[part 2 of 2: packages /AUTOSAR/Csm/ServiceSwComponentTypes_Blueprint to /AUTOSAR/NvM/ServiceSwComponentTypes_Blueprint]
AUTOSAR XML (schema 00046)
package /AUTOSAR/Csm/ServiceSwComponentTypes_Blueprint
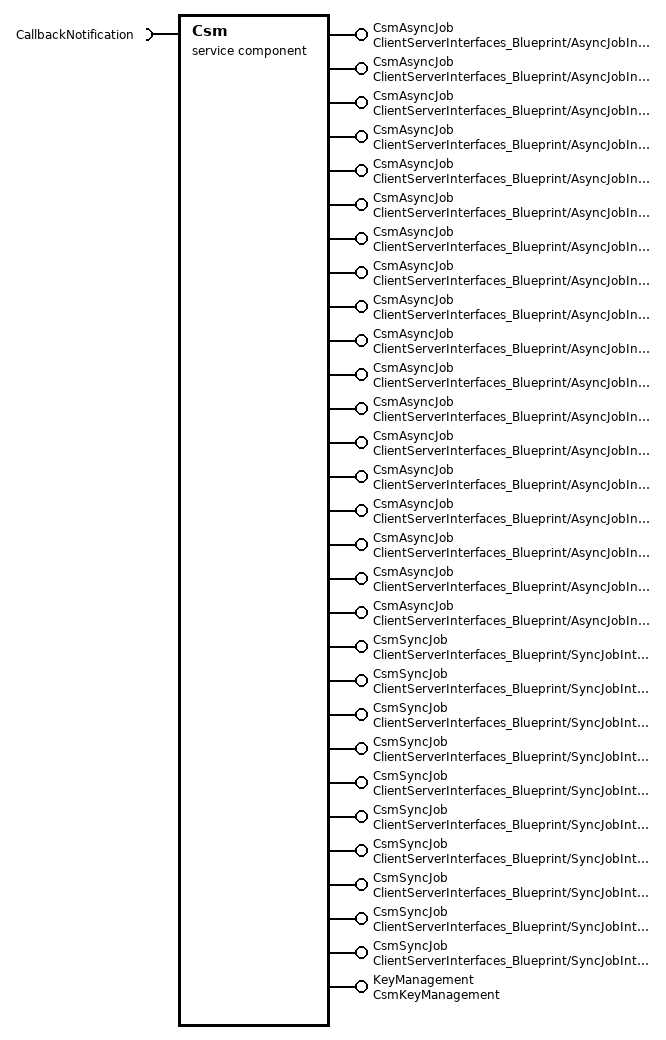
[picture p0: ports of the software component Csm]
  service sw component type Csm
    require port CallbackNotification: variation-point=blueprint-condition=p=l-1=({ecuc(Csm/CsmJobs/CsmJob.CsmProcessingMode)} == CRYPTO_PROCESSING_ASYNC), required-interface=CallbackNotification  # Port for the callback notification.
    29 x provide port:
      CsmAsyncJob: variation-point={short-label=AsyncJobInterface_AsyncCsmHash, blueprint-condition=p=l-1=({ecuc(Csm/CsmJobs/CsmJob.CsmJobInterfaceUsePort)} == CRYPTO_USE_PORT_OPTIMIZED) &&({ecuc(Csm/CsmJobs/CsmJob.CsmJobPrimitiveRef)} != NULL)}, provided-interface=ClientServerInterfaces_Blueprint/AsyncJobInterface  # Port related to a specific cryptographic job to execute the assigned cryptographic calculations asynchronously.
      CsmAsyncJob: variation-point={short-label=AsyncJobInterface_AsyncCsmMacGenerate, blueprint-condition=p=l-1=({ecuc(Csm/CsmJobs/CsmJob.CsmJobInterfaceUsePort)} == CRYPTO_USE_PORT_OPTIMIZED) &&({ecuc(Csm/CsmJobs/CsmJob.CsmJobPrimitiveRef)} != NULL)}, provided-interface=ClientServerInterfaces_Blueprint/AsyncJobInterface  # Port related to a specific cryptographic job to execute the assigned cryptographic calculations asynchronously.
      CsmAsyncJob: variation-point={short-label=AsyncJobInterface_AsyncCsmMacVerify, blueprint-condition=p=l-1=({ecuc(Csm/CsmJobs/CsmJob.CsmJobInterfaceUsePort)} == CRYPTO_USE_PORT_OPTIMIZED) &&({ecuc(Csm/CsmJobs/CsmJob.CsmJobPrimitiveRef)} != NULL)}, provided-interface=ClientServerInterfaces_Blueprint/AsyncJobInterface  # Port related to a specific cryptographic job to execute the assigned cryptographic calculations asynchronously.
      CsmAsyncJob: variation-point={short-label=AsyncJobInterface_AsyncCsmEncrypt, blueprint-condition=p=l-1=({ecuc(Csm/CsmJobs/CsmJob.CsmJobInterfaceUsePort)} == CRYPTO_USE_PORT_OPTIMIZED) &&({ecuc(Csm/CsmJobs/CsmJob.CsmJobPrimitiveRef)} != NULL)}, provided-interface=ClientServerInterfaces_Blueprint/AsyncJobInterface  # Port related to a specific cryptographic job to execute the assigned cryptographic calculations asynchronously.
      CsmAsyncJob: variation-point={short-label=AsyncJobInterface_AsyncCsmDecrypt, blueprint-condition=p=l-1=({ecuc(Csm/CsmJobs/CsmJob.CsmJobInterfaceUsePort)} == CRYPTO_USE_PORT_OPTIMIZED) &&({ecuc(Csm/CsmJobs/CsmJob.CsmJobPrimitiveRef)} != NULL)}, provided-interface=ClientServerInterfaces_Blueprint/AsyncJobInterface  # Port related to a specific cryptographic job to execute the assigned cryptographic calculations asynchronously.
      CsmAsyncJob: variation-point={short-label=AsyncJobInterface_AsyncCsmAEADEncrypt, blueprint-condition=p=l-1=({ecuc(Csm/CsmJobs/CsmJob.CsmJobInterfaceUsePort)} == CRYPTO_USE_PORT_OPTIMIZED) &&({ecuc(Csm/CsmJobs/CsmJob.CsmJobPrimitiveRef)} != NULL)}, provided-interface=ClientServerInterfaces_Blueprint/AsyncJobInterface  # Port related to a specific cryptographic job to execute the assigned cryptographic calculations asynchronously.
      CsmAsyncJob: variation-point={short-label=AsyncJobInterface_AsyncCsmAEADDecrypt, blueprint-condition=p=l-1=({ecuc(Csm/CsmJobs/CsmJob.CsmJobInterfaceUsePort)} == CRYPTO_USE_PORT_OPTIMIZED) &&({ecuc(Csm/CsmJobs/CsmJob.CsmJobPrimitiveRef)} != NULL)}, provided-interface=ClientServerInterfaces_Blueprint/AsyncJobInterface  # Port related to a specific cryptographic job to execute the assigned cryptographic calculations asynchronously.
      CsmAsyncJob: variation-point={short-label=AsyncJobInterface_AsyncCsmSignatureGenerate, blueprint-condition=p=l-1=({ecuc(Csm/CsmJobs/CsmJob.CsmJobInterfaceUsePort)} == CRYPTO_USE_PORT_OPTIMIZED) &&({ecuc(Csm/CsmJobs/CsmJob.CsmJobPrimitiveRef)} != NULL)}, provided-interface=ClientServerInterfaces_Blueprint/AsyncJobInterface  # Port related to a specific cryptographic job to execute the assigned cryptographic calculations asynchronously.
      CsmAsyncJob: variation-point={short-label=AsyncJobInterface_AsyncCsmSignatureVerify, blueprint-condition=p=l-1=({ecuc(Csm/CsmJobs/CsmJob.CsmJobInterfaceUsePort)} == CRYPTO_USE_PORT_OPTIMIZED) &&({ecuc(Csm/CsmJobs/CsmJob.CsmJobPrimitiveRef)} != NULL)}, provided-interface=ClientServerInterfaces_Blueprint/AsyncJobInterface  # Port related to a specific cryptographic job to execute the assigned cryptographic calculations asynchronously.
      CsmAsyncJob: variation-point={short-label=AsyncJobInterface_AsyncCsmRandomGenerate, blueprint-condition=p=l-1=({ecuc(Csm/CsmJobs/CsmJob.CsmJobInterfaceUsePort)} == CRYPTO_USE_PORT_OPTIMIZED) &&({ecuc(Csm/CsmJobs/CsmJob.CsmJobPrimitiveRef)} != NULL)}, provided-interface=ClientServerInterfaces_Blueprint/AsyncJobInterface  # Port related to a specific cryptographic job to execute the assigned cryptographic calculations asynchronously.
      CsmAsyncJob: variation-point={short-label=AsyncJobInterface_JobCertificateParse, blueprint-condition=p=l-1=({ecuc(Csm/CsmJobs/CsmJob.CsmJobInterfaceUsePort)} == CRYPTO_USE_PORT_OPTIMIZED) &&({ecuc(Csm/CsmJobs/CsmJob.CsmJobPrimitiveRef)} != NULL)}, provided-interface=ClientServerInterfaces_Blueprint/AsyncJobInterface  # Port related to a specific cryptographic job to execute the assigned cryptographic calculations asynchronously.
      CsmAsyncJob: variation-point={short-label=AsyncJobInterface_JobCertificateVerify, blueprint-condition=p=l-1=({ecuc(Csm/CsmJobs/CsmJob.CsmJobInterfaceUsePort)} == CRYPTO_USE_PORT_OPTIMIZED) &&({ecuc(Csm/CsmJobs/CsmJob.CsmJobPrimitiveRef)} != NULL)}, provided-interface=ClientServerInterfaces_Blueprint/AsyncJobInterface  # Port related to a specific cryptographic job to execute the assigned cryptographic calculations asynchronously.
      CsmAsyncJob: variation-point={short-label=AsyncJobInterface_JobKeyDerive, blueprint-condition=p=l-1=({ecuc(Csm/CsmJobs/CsmJob.CsmJobInterfaceUsePort)} == CRYPTO_USE_PORT_OPTIMIZED) &&({ecuc(Csm/CsmJobs/CsmJob.CsmJobPrimitiveRef)} != NULL)}, provided-interface=ClientServerInterfaces_Blueprint/AsyncJobInterface  # Port related to a specific cryptographic job to execute the assigned cryptographic calculations asynchronously.
      CsmAsyncJob: variation-point={short-label=AsyncJobInterface_JobKeyExchangeCalcPubVal, blueprint-condition=p=l-1=({ecuc(Csm/CsmJobs/CsmJob.CsmJobInterfaceUsePort)} == CRYPTO_USE_PORT_OPTIMIZED) &&({ecuc(Csm/CsmJobs/CsmJob.CsmJobPrimitiveRef)} != NULL)}, provided-interface=ClientServerInterfaces_Blueprint/AsyncJobInterface  # Port related to a specific cryptographic job to execute the assigned cryptographic calculations asynchronously.
      CsmAsyncJob: variation-point={short-label=AsyncJobInterface_JobKeyExchangeCalcSecret, blueprint-condition=p=l-1=({ecuc(Csm/CsmJobs/CsmJob.CsmJobInterfaceUsePort)} == CRYPTO_USE_PORT_OPTIMIZED) &&({ecuc(Csm/CsmJobs/CsmJob.CsmJobPrimitiveRef)} != NULL)}, provided-interface=ClientServerInterfaces_Blueprint/AsyncJobInterface  # Port related to a specific cryptographic job to execute the assigned cryptographic calculations asynchronously.
      CsmAsyncJob: variation-point={short-label=AsyncJobInterface_JobKeyGenerate, blueprint-condition=p=l-1=({ecuc(Csm/CsmJobs/CsmJob.CsmJobInterfaceUsePort)} == CRYPTO_USE_PORT_OPTIMIZED) &&({ecuc(Csm/CsmJobs/CsmJob.CsmJobPrimitiveRef)} != NULL)}, provided-interface=ClientServerInterfaces_Blueprint/AsyncJobInterface  # Port related to a specific cryptographic job to execute the assigned cryptographic calculations asynchronously.
      CsmAsyncJob: variation-point={short-label=AsyncJobInterface_JobKeySetValid, blueprint-condition=p=l-1=({ecuc(Csm/CsmJobs/CsmJob.CsmJobInterfaceUsePort)} == CRYPTO_USE_PORT_OPTIMIZED) &&({ecuc(Csm/CsmJobs/CsmJob.CsmJobPrimitiveRef)} != NULL)}, provided-interface=ClientServerInterfaces_Blueprint/AsyncJobInterface  # Port related to a specific cryptographic job to execute the assigned cryptographic calculations asynchronously.
      CsmAsyncJob: variation-point={short-label=AsyncJobInterface_JobRandomSeed, blueprint-condition=p=l-1=({ecuc(Csm/CsmJobs/CsmJob.CsmJobInterfaceUsePort)} == CRYPTO_USE_PORT_OPTIMIZED) &&({ecuc(Csm/CsmJobs/CsmJob.CsmJobPrimitiveRef)} != NULL)}, provided-interface=ClientServerInterfaces_Blueprint/AsyncJobInterface  # Port related to a specific cryptographic job to execute the assigned cryptographic calculations asynchronously.
      CsmSyncJob: variation-point={short-label=SyncJobInterface_SyncCsmHash, blueprint-condition=p=l-1=({ecuc(Csm/CsmJobs/CsmJob.CsmJobInterfaceUsePort)} == CRYPTO_USE_PORT) &&({ecuc(Csm/CsmJobs/CsmJob.CsmJobPrimitiveRef)} != NULL)}, provided-interface=ClientServerInterfaces_Blueprint/SyncJobInterface  # Port related to a specific cryptographic job to execute the assigned cryptographic calculations synchronously.
      CsmSyncJob: variation-point={short-label=SyncJobInterface_SyncCsmMacGenerate, blueprint-condition=p=l-1=({ecuc(Csm/CsmJobs/CsmJob.CsmJobInterfaceUsePort)} == CRYPTO_USE_PORT) &&({ecuc(Csm/CsmJobs/CsmJob.CsmJobPrimitiveRef)} != NULL)}, provided-interface=ClientServerInterfaces_Blueprint/SyncJobInterface  # Port related to a specific cryptographic job to execute the assigned cryptographic calculations synchronously.
      CsmSyncJob: variation-point={short-label=SyncJobInterface_SyncCsmMacVerify, blueprint-condition=p=l-1=({ecuc(Csm/CsmJobs/CsmJob.CsmJobInterfaceUsePort)} == CRYPTO_USE_PORT) &&({ecuc(Csm/CsmJobs/CsmJob.CsmJobPrimitiveRef)} != NULL)}, provided-interface=ClientServerInterfaces_Blueprint/SyncJobInterface  # Port related to a specific cryptographic job to execute the assigned cryptographic calculations synchronously.
      CsmSyncJob: variation-point={short-label=SyncJobInterface_SyncCsmEncrypt, blueprint-condition=p=l-1=({ecuc(Csm/CsmJobs/CsmJob.CsmJobInterfaceUsePort)} == CRYPTO_USE_PORT) &&({ecuc(Csm/CsmJobs/CsmJob.CsmJobPrimitiveRef)} != NULL)}, provided-interface=ClientServerInterfaces_Blueprint/SyncJobInterface  # Port related to a specific cryptographic job to execute the assigned cryptographic calculations synchronously.
      CsmSyncJob: variation-point={short-label=SyncJobInterface_SyncCsmDecrypt, blueprint-condition=p=l-1=({ecuc(Csm/CsmJobs/CsmJob.CsmJobInterfaceUsePort)} == CRYPTO_USE_PORT) &&({ecuc(Csm/CsmJobs/CsmJob.CsmJobPrimitiveRef)} != NULL)}, provided-interface=ClientServerInterfaces_Blueprint/SyncJobInterface  # Port related to a specific cryptographic job to execute the assigned cryptographic calculations synchronously.
      CsmSyncJob: variation-point={short-label=SyncJobInterface_SyncCsmAEADEncrypt, blueprint-condition=p=l-1=({ecuc(Csm/CsmJobs/CsmJob.CsmJobInterfaceUsePort)} == CRYPTO_USE_PORT) &&({ecuc(Csm/CsmJobs/CsmJob.CsmJobPrimitiveRef)} != NULL)}, provided-interface=ClientServerInterfaces_Blueprint/SyncJobInterface  # Port related to a specific cryptographic job to execute the assigned cryptographic calculations synchronously.
      CsmSyncJob: variation-point={short-label=SyncJobInterface_SyncCsmAEADDecrypt, blueprint-condition=p=l-1=({ecuc(Csm/CsmJobs/CsmJob.CsmJobInterfaceUsePort)} == CRYPTO_USE_PORT) &&({ecuc(Csm/CsmJobs/CsmJob.CsmJobPrimitiveRef)} != NULL)}, provided-interface=ClientServerInterfaces_Blueprint/SyncJobInterface  # Port related to a specific cryptographic job to execute the assigned cryptographic calculations synchronously.
      CsmSyncJob: variation-point={short-label=SyncJobInterface_SyncCsmSignatureGenerate, blueprint-condition=p=l-1=({ecuc(Csm/CsmJobs/CsmJob.CsmJobInterfaceUsePort)} == CRYPTO_USE_PORT) &&({ecuc(Csm/CsmJobs/CsmJob.CsmJobPrimitiveRef)} != NULL)}, provided-interface=ClientServerInterfaces_Blueprint/SyncJobInterface  # Port related to a specific cryptographic job to execute the assigned cryptographic calculations synchronously.
      CsmSyncJob: variation-point={short-label=SyncJobInterface_SyncCsmSignatureVerify, blueprint-condition=p=l-1=({ecuc(Csm/CsmJobs/CsmJob.CsmJobInterfaceUsePort)} == CRYPTO_USE_PORT) &&({ecuc(Csm/CsmJobs/CsmJob.CsmJobPrimitiveRef)} != NULL)}, provided-interface=ClientServerInterfaces_Blueprint/SyncJobInterface  # Port related to a specific cryptographic job to execute the assigned cryptographic calculations synchronously.
      CsmSyncJob: variation-point={short-label=SyncJobInterface_SyncCsmRandomGenerate, blueprint-condition=p=l-1=({ecuc(Csm/CsmJobs/CsmJob.CsmJobInterfaceUsePort)} == CRYPTO_USE_PORT) &&({ecuc(Csm/CsmJobs/CsmJob.CsmJobPrimitiveRef)} != NULL)}, provided-interface=ClientServerInterfaces_Blueprint/SyncJobInterface  # Port related to a specific cryptographic job to execute the assigned cryptographic calculations synchronously.
      KeyManagement: variation-point=blueprint-condition=p=l-1={ecuc(Csm/CsmKeys/CsmKey.CsmKeyUsePort)} == TRUE, provided-interface=CsmKeyManagement  # Port related to a specific cryptographic key to execute the key management functions synchronously.
    behavior CsmInternalBehavior
      port-api-options:
        {port-arg-values=[{value=undefined, value-type=uint32}, {value=undefined, value-type=Crypto_OperationModeType}], port=Csm/CsmAsyncJob}
        {port-arg-values=[{value=undefined, value-type=uint32}, {value=undefined, value-type=Crypto_OperationModeType}], port=Csm/CsmSyncJob}
        {port-defined-argument-value{value=undefined, value-type=uint32}, port=KeyManagement}
package /AUTOSAR/Mirror/ClientServerInterfaces_Blueprint
  client server interface MirrorControl: is-service=true  # Provides access to the control functions of the Bus Mirroring module.
    18 x operation:
      AddCanMaskFilter: possible-error=[MirrorControl/E_OK, MirrorControl/E_NOT_OK]  # Creates a CAN ID mask filter.
        4 x arg:
          network: type=NetworkHandleType, direction=IN  # ComM channel that corresponds to the CAN bus to which the filter shall be attached.
          filterId: category=DATA_REFERENCE, type=Mirror_uint8Ptr, direction=OUT  # ID of the newly created filter.
          id: type=Mirror_CanIdType, direction=IN  # CAN ID used to match a received or transmitted CAN ID.
          mask: type=Mirror_CanIdType, direction=IN  # Mask that defines the bits of 'id' that are relevant for comparison with the actual CAN ID.
      AddCanRangeFilter: possible-error=[MirrorControl/E_OK, MirrorControl/E_NOT_OK]  # Creates a CAN ID range filter.
        4 x arg:
          network: type=NetworkHandleType, direction=IN  # ComM channel that corresponds to the CAN bus to which the filter shall be attached.
          filterId: category=DATA_REFERENCE, type=Mirror_uint8Ptr, direction=OUT  # ID of the newly created filter.
          lowerId: type=Mirror_CanIdType, direction=IN  # Lower CAN ID of the range.
          upperId: type=Mirror_CanIdType, direction=IN  # Upper CAN ID of the range.
      AddFlexRayFilter: possible-error=[MirrorControl/E_OK, MirrorControl/E_NOT_OK]  # Creates a FlexRay filter.
        8 x arg:
          network: type=NetworkHandleType, direction=IN  # ComM channel that corresponds to the FlexRay bus to which the filter shall be attached.
          filterId: category=DATA_REFERENCE, type=Mirror_uint8Ptr, direction=OUT  # ID of the newly created filter.
          lowerSlotId: type=uint16, direction=IN  # Lower slot ID of a range of slot IDs.
          upperSlotId: type=uint16, direction=IN  # Upper slot ID of a range of slot IDs.
          lowerBaseCycle: type=uint8, direction=IN  # Lower base cycle of a range of cycles.
          upperBaseCycle: type=uint8, direction=IN  # Upper base cycle of a range of cycles.
          cycleRepetition: type=uint8, direction=IN  # Repetition pattern of selected cycles (2^n).
          frChannel: type=Mirror_FlexRayChannelType, direction=IN  # FlexRay channel assignment.
      AddLinMaskFilter: possible-error=[MirrorControl/E_OK, MirrorControl/E_NOT_OK]  # Creates a LIN frame ID mask filter.
        4 x arg:
          network: type=NetworkHandleType, direction=IN  # ComM channel that corresponds to the LIN bus to which the filter shall be attached.
          filterId: category=DATA_REFERENCE, type=Mirror_uint8Ptr, direction=OUT  # ID of the newly created filter.
          id: type=uint8, direction=IN  # Frame ID used to match a received or transmitted frame ID.
          mask: type=uint8, direction=IN  # Mask that defines the bits of 'id' that are relevant for comparison with the actual frame ID.
      AddLinRangeFilter: possible-error=[MirrorControl/E_OK, MirrorControl/E_NOT_OK]  # Creates a LIN frame ID range filter.
        4 x arg:
          network: type=NetworkHandleType, direction=IN  # ComM channel that corresponds to the LIN bus to which the filter shall be attached.
          filterId: category=DATA_REFERENCE, type=Mirror_uint8Ptr, direction=OUT  # ID of the newly created filter.
          lowerId: type=uint8, direction=IN  # Lower frame ID of the range.
          upperId: type=uint8, direction=IN  # Upper frame ID of the range.
      GetDestNetwork: possible-error=MirrorControl/E_OK  # Returns the currently selected destination bus.
        arg network: type=NetworkHandleType, direction=OUT  # ComM channel that corresponds to the currently active destination network.
      GetNetworkHandle: possible-error=[MirrorControl/E_OK, MirrorControl/E_NOT_OK]  # Returns the network handle (ComMChannel) of the bus identified by the given network type and network ID.
        arg networkType: type=Mirror_NetworkType, direction=IN  # Network type of the bus to be identified.
        arg networkId: type=uint8, direction=IN  # Network ID of the bus to be identified.
        arg network: type=NetworkHandleType, direction=OUT  # ComM channel that corresponds to the bus identified by the given network type and network ID.
      GetNetworkId: possible-error=[MirrorControl/E_OK, MirrorControl/E_NOT_OK]  # Returns the network ID of the given network.
        arg network: type=NetworkHandleType, direction=IN  # ComM channel corresponding to one of the buses configured as source or destination bus.
        arg networkId: type=uint8, direction=OUT  # Network ID of the bus identified by 'network'.
      GetNetworkType: possible-error=[MirrorControl/E_OK, MirrorControl/E_NOT_OK]  # Returns the network type of the given network.
        arg network: type=NetworkHandleType, direction=IN  # ComM channel corresponding to one of the buses configured as source or destination bus.
        arg networkType: type=Mirror_NetworkType, direction=OUT  # Network type of the bus identified by 'network'.
      GetStaticFilterState: possible-error=[MirrorControl/E_OK, MirrorControl/E_NOT_OK]  # Returns the state of a pre-configured filter.
        arg network: type=NetworkHandleType, direction=IN  # ComM channel that corresponds to the source bus to which the filter is attached.
        arg filterId: type=uint8, direction=IN  # ID of the filter.
        arg isActive: category=DATA_REFERENCE, type=Mirror_booleanPtr, direction=OUT  # Pointer to where to store the current filter state.
      IsMirrorActive: possible-error=MirrorControl/E_OK  # Returns the global mirroring state.
        arg mirrorActive: type=boolean, direction=OUT  # Global mirroring state.
      IsSourceNetworkStarted: possible-error=MirrorControl/E_OK  # Returns the state of a source bus.
        arg network: type=NetworkHandleType, direction=IN  # ComM channel corresponding to the source bus that shall be checked.
        arg sourceNetworkStarted: type=boolean, direction=OUT  # State of a source bus. TRUE: Source bus is active. FALSE: Source bus is inactive.
      Offline: possible-error=MirrorControl/E_OK  # Completely disables any mirroring activities. Source buses are reset to disabled, queued messages are purged, and the destination bus is reset to the default destination. Pre-configured filters are disabled, and filters added at runtime are removed.
      RemoveFilter: possible-error=[MirrorControl/E_OK, MirrorControl/E_NOT_OK]  # Removes a CAN, LIN, or FlexRay filter that was added at runtime.
        arg network: type=NetworkHandleType, direction=IN  # ComM channel that corresponds to the source bus to which the filter is attached.
        arg filterId: type=uint8, direction=IN  # ID of the filter.
      SetStaticFilterState: possible-error=[MirrorControl/E_OK, MirrorControl/E_NOT_OK]  # Sets the state of a pre-configured filter.
        arg network: type=NetworkHandleType, direction=IN  # ComM channel that corresponds to the source bus to which the filter is attached.
        arg filderId: type=uint8, direction=IN  # ID of the filter.
        arg isActive: type=boolean, direction=IN  # TRUE: Activate filter FALSE: Deactivate filter
      StartSourceNetwork: possible-error=[MirrorControl/E_OK, MirrorControl/E_NOT_OK]  # Activates a source bus.
        arg network: type=NetworkHandleType, direction=IN  # ComM channel corresponding to the source bus that shall be started.
      StopSourceNetwork: possible-error=[MirrorControl/E_OK, MirrorControl/E_NOT_OK]  # Deactivates a source bus.
        arg network: type=NetworkHandleType, direction=IN  # ComM channel corresponding to the source bus that shall be stopped.
      SwitchDestNetwork: possible-error=[MirrorControl/E_OK, MirrorControl/E_NOT_OK]  # Changes the destination bus to the given ComM channel. The previously active destination bus and all source buses are disabled.
        arg network: type=NetworkHandleType, direction=IN  # ComM channel corresponding to the destination bus that shall be enabled.
    error E_OK: error-code=0  # Operation successful
    error E_NOT_OK: error-code=1  # Operation failed
package /AUTOSAR/Mirror/ServiceSwComponentTypes_Blueprint
  service sw component type Mirror
    provide port MirrorControl: provided-interface=MirrorControl  # Provided port for the interface MirrorControl.
    behavior MirrorInternalBehavior
package /AUTOSAR/DoIP/ClientServerInterfaces_Blueprint
  5 x client server interface, all with is-service=true:
    CallbackGetFurtherActionByte: variation-point={short-label=CallbackGetFurtherActionByte, blueprint-condition=p=l-1={ecuc(DoIP/DoIPGeneral/DoIPFurtherActionByteCallback/DoIPFurtherActionByteDirect)} == NULL}
      operation GetFurtherActionByte: possible-error=[CallbackGetFurtherActionByte/E_OK, CallbackGetFurtherActionByte/E_NOT_OK]
        arg FurtherActionByte: type=DoIP_FurtherActionByteType, direction=OUT
      error E_OK: error-code=0  # Operation successful
      error E_NOT_OK: error-code=1  # Operation failed
    CallbackGetGID: variation-point={short-label=CallbackGetGID, blueprint-condition=p=l-1=({ecuc(DoIP/DoIPGeneral/DoIPGetGidCallback)} != NULL) && ({ecuc(DoIP/DoIPGeneral/DoIPGetGidCallback/DoIPGetGidDirect)} == NULL)}
      operation GetGID: possible-error=[CallbackGetGID/E_OK, CallbackGetGID/E_NOT_OK]
        arg Data: type=uint8, direction=OUT
      error E_OK: error-code=0  # Operation successful
      error E_NOT_OK: error-code=1  # Operation failed
    CallbackGetPowerMode: variation-point={short-label=CallbackGetPowerMode, blueprint-condition=p=l-1={ecuc(DoIP/DoIPGeneral/DoIPPowerModeCallback/DoIPPowerModeDirect)} == NULL}
      operation GetPowerMode: possible-error=[CallbackGetPowerMode/E_OK, CallbackGetPowerMode/E_NOT_OK]
        arg PowerStateReady: type=DoIP_PowerStateType, direction=OUT
      error E_OK: error-code=0  # Operation successful
      error E_NOT_OK: error-code=1  # Operation failed
    CallbackTriggerGIDSynchronization: variation-point={short-label=CallbackTriggerGIDSynchronization, blueprint-condition=p=l-1=({ecuc(DoIP/DoIPGeneral/DoIPTriggerGidSyncCallback)} != NULL) && ({ecuc(DoIP/DoIPGeneral/DoIPTriggerGidSyncCallback/DoIPTriggerGidSyncDirect)} == NULL) && ({ecuc(DoIP/DoIPGeneral/DoIPVinGidMaster)} == TRUE)}
      operation TriggerGIDSynchronization: possible-error=[CallbackTriggerGIDSynchronization/E_OK, CallbackTriggerGIDSynchronization/E_NOT_OK]
      error E_OK: error-code=0  # Operation successful
      error E_NOT_OK: error-code=1  # Operation failed
    RoutingActivation: variation-point={short-label=RoutingActivation, blueprint-condition=p=l-1=(({ecuc(DoIP/DoIPConfigSet/DoIPRoutingActivation/DoIPRoutingActivationAuthenticationCallback)} != null) && ({ecuc(DoIP/DoIPConfigSet/DoIPRoutingActivation/DoIPRoutingActivationAuthenticationCallback/DoIPRoutingActivationAuthenticationFunc)} == "")) || (({ecuc(DoIP/DoIPConfigSet/DoIPRoutingActivation/DoIPRoutingActivationConfirmationCallback)} != null) && ({ecuc(DoIP/DoIPConfigSet/DoIPRoutingActivation/DoIPRoutingActivationConfirmationCallback/DoIPRoutingActivationConfirmationFunc)} == ""))}
      operation RoutingActivationAuthentication: possible-error=[RoutingActivation/E_OK, RoutingActivation/E_NOT_OK, DOIP_E_PENDING], variation-point=blueprint-condition=p=l-1=(({ecuc(DoIP/DoIPConfigSet/DoIPRoutingActivation/DoIPRoutingActivationAuthenticationCallback)} != NULL) && ({ecuc(DoIP/DoIPConfigSet/DoIPRoutingActivation/DoIPRoutingActivationAuthenticationCallback/DoIPRoutingActivationAuthenticationFunc)} ==NULL))
        arg Authentified: type=boolean, direction=OUT
        arg AuthenticationReqData: type=AuthenticationReqDataType, direction=IN, variation-point=blueprint-condition=p=l-1={ecuc(DoIP/DoIPConfigSet/DoIPRoutingActivation/DoIPRoutingActivationAuthenticationCallback.DoIPRoutingActivationAuthenticationReqLength)} > 0
        arg AuthenticationResData: type=AuthenticationResDataType, direction=OUT, variation-point=blueprint-condition=p=l-1={ecuc(DoIP/DoIPConfigSet/DoIPRoutingActivation/DoIPRoutingActivationAuthenticationCallback.DoIPRoutingActivationAuthenticationResLength)} > 0
      operation RoutingActivationConfirmation: possible-error=[RoutingActivation/E_OK, RoutingActivation/E_NOT_OK, DOIP_E_PENDING], variation-point=blueprint-condition=p=l-1=(({ecuc(DoIP/DoIPConfigSet/DoIPRoutingActivation/DoIPRoutingActivationConfirmationCallback)} != NULL) && ({ecuc(DoIP/DoIPConfigSet/DoIPRoutingActivation/DoIPRoutingActivationConfirmationCallback/DoIPRoutingActivationConfirmationFunc)} ==NULL))
        arg Confirmed: type=boolean, direction=OUT
        arg ConfirmedReqData: type=ConfirmationReqDataType, direction=IN, variation-point=blueprint-condition=p=l-1={ecuc(DoIP/DoIPConfigSet/DoIPRoutingActivation/DoIPRoutingActivationConfirmationCallback.DoIPRoutingActivationConfirmationReqLength)} > 0
        arg ConfirmedResData: type=ConfirmationResDataType, direction=OUT, variation-point=blueprint-condition=p=l-1={ecuc(DoIP/DoIPConfigSet/DoIPRoutingActivation/DoIPRoutingActivationConfirmationCallback.DoIPRoutingActivationConfirmationResLength)} > 0
      error E_OK: error-code=0  # Operation successful
      error E_NOT_OK: error-code=1  # Operation failed
      error DOIP_E_PENDING: error-code=16  # RoutingActivation still pending.
package /AUTOSAR/DoIP/ServiceSwComponentTypes_Blueprint
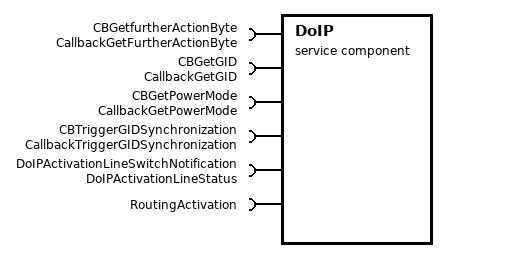
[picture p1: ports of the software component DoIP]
  service sw component type DoIP
    6 x require port:
      CBGetfurtherActionByte: variation-point=blueprint-condition=p=l-1={ecuc(DoIP/DoIPGeneral/DoIPFurtherActionByteCallback/DoIPFurtherActionByteDirect)} == NULL, required-interface=CallbackGetFurtherActionByte
      CBGetGID: variation-point=blueprint-condition=p=l-1=({ecuc(DoIP/DoIPGeneral/DoIPGetGidCallback)} != NULL) && ({ecuc(DoIP/DoIPGeneral/DoIPGetGidCallback/DoIPGetGidDirect)} == NULL), required-interface=CallbackGetGID
      CBGetPowerMode: variation-point=blueprint-condition=p=l-1={ecuc(DoIP/DoIPGeneral/DoIPPowerModeCallback/DoIPPowerModeDirect)} == NULL, required-interface=CallbackGetPowerMode
      CBTriggerGIDSynchronization: variation-point=blueprint-condition=p=l-1=({ecuc(DoIP/DoIPGeneral/DoIPTriggerGidSyncCallback)} != NULL) && ({ecuc(DoIP/DoIPGeneral/DoIPTriggerGidSyncCallback/DoIPTriggerGidSyncDirect)} == NULL) && ({ecuc(DoIP/DoIPGeneral/DoIPVinGidMaster)} == TRUE), required-interface=CallbackTriggerGIDSynchronization
      DoIPActivationLineSwitchNotification: required-interface=DoIPActivationLineStatus
      RoutingActivation: required-interface=RoutingActivation
    behavior DoIPInternalBehavior
package /AUTOSAR/DoIP/ModeDeclarationGroups_Blueprint
  mode declaration group DoIP_ActivationLineType: category=ALPHABETIC_ORDER, initial-mode=DOIP_ACTIVATION_LINE_INACTIVE
    mode DOIP_ACTIVATION_LINE_ACTIVE
    mode DOIP_ACTIVATION_LINE_INACTIVE
package /AUTOSAR/DoIP/ModeSwitchInterfaces_Blueprint
  mode switch interface DoIPActivationLineStatus: is-service=true
    mode group currentDoIPActivationLineStatus: type=DoIP_ActivationLineType
package /AUTOSAR/J1939Dcm/ClientServerInterfaces_Blueprint
  client server interface J1939Dcm_CalibrationInformation: variation-point={short-label=J1939Dcm_CalibrationInformation, blueprint-condition=p=l-1={ecuc(J1939Dcm/J1939DcmConfigSet/J1939DcmNode/J1939DcmDiagnosticMessageSupport.J1939DcmDmxSupport)} == J1939DcmDm19Support}, is-service=true
    operation GetCalibrationVerificationNumber: possible-error=[J1939Dcm_CalibrationInformation/E_OK, E_NOT_READY, E_NEXT]
      arg CalibrationVerificationNumber: type=uint32, direction=OUT
      arg CalibrationID: type=CalibrationIDArrayType, direction=OUT
    error E_OK: error-code=0  # Operation successful
    error E_NOT_READY: error-code=1  # E_NOT_READY is used if the CVN calculation is not finished yet. The tool needs to send the request again.
    error E_NEXT: error-code=2  # E_NEXT is used if the CVN calculation is finished, but not all CVNs returned yet.
package /AUTOSAR/J1939Dcm/SenderReceiverInterfaces_Blueprint
  sender receiver interface DataCondition: variation-point={short-label=DataCondition, blueprint-condition=p=l-1=({ecuc(J1939Dcm/J1939DcmConfigSet/J1939DcmProcessingConditions/J1939DcmModeCondition/J1939DcmSwcSRDataElementRef)} != NULL)}
    data data:
      variation-point=blueprint-condition=p=l-1=({ecuc(J1939Dcm/J1939DcmConfigSet/J1939DcmProcessingConditions/J1939DcmModeCondition/J1939DcmSwcSRDataElementRef->J1939DcmDataElementInstance/J1939DcmDataElementInstanceRef)} != NULL)
      variation-point=blueprint-condition=p=l-1=({ecuc(J1939Dcm/J1939DcmConfigSet/J1939DcmProcessingConditions/J1939DcmModeCondition/J1939DcmSwcSRDataElementRef->J1939DcmSubElementInDataElementInstance/J1939DcmSubElementInDataElementInstanceRef)} != NULL)
      variation-point=blueprint-condition=p=l-1=({ecuc(J1939Dcm/J1939DcmConfigSet/J1939DcmProcessingConditions/J1939DcmModeCondition/J1939DcmSwcSRDataElementRef->J1939DcmSubElementInImplDataElementInstance/J1939DcmSubElementInImplDataElementInstanceRef)} != NULL)
package /AUTOSAR/J1939Dcm/ServiceSwComponentTypes_Blueprint
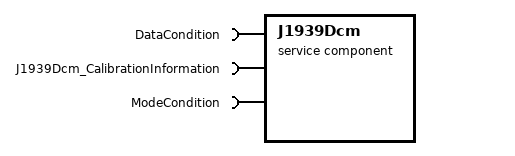
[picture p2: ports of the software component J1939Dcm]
  service sw component type J1939Dcm
    require port DataCondition: variation-point=blueprint-condition=p=l-1=({ecuc(J1939Dcm/J1939DcmConfigSet/J1939DcmProcessingConditions/J1939DcmModeCondition/J1939DcmSwcSRDataElementRef)} != NULL), required-interface=DataCondition
    require port J1939Dcm_CalibrationInformation: variation-point=blueprint-condition=p=l-1={ecuc(J1939Dcm/J1939DcmConfigSet/J1939DcmNode/J1939DcmDiagnosticMessageSupport.J1939DcmDmxSupport)} == J1939DcmDm19Support, required-interface=J1939Dcm_CalibrationInformation  # Port to retrieve the Calibration Verification Numbers (CVNs) from the application.
    require port ModeCondition: variation-point=blueprint-condition=p=l-1=({ecuc(J1939Dcm/J1939DcmConfigSet/J1939DcmProcessingConditions/J1939DcmModeCondition/J1939DcmSwcModeRef)} != NULL)
    behavior J1939DcmInternalBehavior
package /AUTOSAR/J1939Rm/ClientServerInterfaces_Blueprint
  6 x client server interface, all with is-service=true:
    AppAckIndication: variation-point={short-label=AppAckIndication, blueprint-condition=p=l-1={ecuc(J1939Rm/J1939RmGeneral.J1939RmSupportAckIndication)} == true}
      operation AckIndication: possible-error=[AppAckIndication/E_OK, AppAckIndication/E_NOT_OK]  # Indicates reception of an Acknowledgement PG.
        8 x arg, all with direction=IN:
          node: type=uint8  # Node by which the acknowledgement was received.
          channel: type=NetworkHandleType  # Channel on which the acknowledgement was received.
          ackPgn: type=uint32  # Acknowledged PGN.
          extIdInfo: type=J1939Rm_ExtIdInfoType  # Extended identifier bytes.
          ackCode: type=J1939Rm_AckCode  # Type of acknowledgement, see definition of J1939Rm_AckCode for available codes.
          ackAddress: type=uint8  # Address of this node.
          sourceAddress: type=uint8  # Address of the node that sent the Acknowledgement PG.
          priority: type=uint8  # Priority of the Acknowledgement PG.
      error E_OK: error-code=0  # Operation successful
      error E_NOT_OK: error-code=1  # Operation failed
    AppCancelRequestTimeout: variation-point={short-label=AppCancelRequestTimeout, blueprint-condition=p=l-1={ecuc(J1939Rm/J1939RmGeneral.J1939RmSupportTimeoutSupervision)} == true}
      operation CancelRequestTimeout: possible-error=[AppCancelRequestTimeout/E_OK, AppCancelRequestTimeout/E_NOT_OK]  # Cancels timeout monitoring of a request. If the request is not active, or timeout monitoring was not requested, this call has no effect.
        4 x arg, all with direction=IN:
          channel: type=NetworkHandleType  # Channel on which the request was sent.
          requestedPgn: type=uint32  # PGN of the requested PG.
          extIdInfo: type=J1939Rm_ExtIdInfoType
          destAddress: type=uint8  # Address of the destination node or 0xFF for broadcast.
      error E_OK: error-code=0  # Operation successful
      error E_NOT_OK: error-code=1  # Operation failed
    AppRequestIndication: variation-point={short-label=AppRequestIndication, blueprint-condition=p=l-1={ecuc(J1939Rm/J1939RmGeneral.J1939RmSupportRequestIndication)} == true}
      operation RequestIndication: possible-error=[AppRequestIndication/E_OK, AppRequestIndication/E_NOT_OK]  # Indicates reception of a Request or Request2 PG.
        7 x arg, all with direction=IN:
          node: type=uint8  # Node by which the request was received.
          channel: type=NetworkHandleType  # Channel on which the request was received.
          requestedPgn: type=uint32  # PGN of the requested PG.
          extIdInfo: type=J1939Rm_ExtIdInfoType  # Extended identifier bytes.
          sourceAddress: type=uint8  # Address of the node that sent the Request PG.
          destAddress: type=uint8  # Address of this node or 0xFF for broadcast.
          priority: type=uint8  # Priority of the Request PG.
      error E_OK: error-code=0  # Operation successful
      error E_NOT_OK: error-code=1  # Operation failed
    AppRequestTimeoutIndication: variation-point={short-label=AppRequestTimeoutIndication, blueprint-condition=p=l-1={ecuc(J1939Rm/J1939RmGeneral.J1939RmSupportTimeoutSupervision)} == true}
      operation RequestTimeoutIndication: possible-error=[AppRequestTimeoutIndication/E_OK, AppRequestTimeoutIndication/E_NOT_OK]  # Indicates timeout of a request triggered with the same parameters.
        5 x arg, all with direction=IN:
          node: type=uint8  # Node by which the request was sent.
          channel: type=NetworkHandleType  # Channel on which the request was sent.
          requestedPgn: type=uint32  # PGN of the requested PG.
          extIdInfo: type=J1939Rm_ExtIdInfoType  # Extended identifier bytes.
          destAddress: type=uint8  # Address of the destination node or 0xFF for broadcast.
      error E_OK: error-code=0  # Operation successful
      error E_NOT_OK: error-code=1  # Operation failed
    AppSendAck: variation-point={short-label=AppSendAck, blueprint-condition=p=l-1={ecuc(J1939Rm/J1939RmGeneral.J1939RmSupportAckTransmission)} == true}
      operation SendAck: possible-error=[AppSendAck/E_OK, AppSendAck/E_NOT_OK]  # Requests transmission of an Acknowledgement PG.
        7 x arg, all with direction=IN:
          channel: type=NetworkHandleType  # Channel on which the acknowledgement shall be sent.
          ackPgn: type=uint32  # Acknowledged PGN.
          extIdInfo: type=J1939Rm_ExtIdInfoType
          ackCode: type=J1939Rm_AckCode  # Type of acknowledgement, see definition of J1939Rm_AckCode for available codes.
          ackAddress: type=uint8  # Address of the node that sent the request.
          priority: type=uint8  # Priority of the Acknowledgement PG.
          broadcast: type=boolean  # Indicates whether the ACKM is a response to a broadcast request.
      error E_OK: error-code=0  # Operation successful
      error E_NOT_OK: error-code=1  # Operation failed
    AppSendRequest: variation-point={short-label=AppSendRequest, blueprint-condition=p=l-1={ecuc(J1939Rm/J1939RmGeneral.J1939RmSupportRequestTransmission)} == true}
      operation SendRequest: possible-error=[AppSendRequest/E_OK, AppSendRequest/E_NOT_OK]  # Requests transmission of a Request or Request2 PG.
        6 x arg, all with direction=IN:
          channel: type=NetworkHandleType  # Channel on which the request shall be sent.
          requestedPgn: type=uint32  # PGN of the requested PG.
          extIdInfo: type=J1939Rm_ExtIdInfoType
          destAddress: type=uint8  # Address of the destination node or 0xFF for broadcast.
          priority: type=uint8  # Priority of the Request PG.
          checkTimeout: type=boolean  # TRUE: Timeout supervision will be performed FALSE: No timeout supervision will be started
      error E_OK: error-code=0  # Operation successful
      error E_NOT_OK: error-code=1  # Operation failed
package /AUTOSAR/J1939Rm/ServiceSwComponentTypes_Blueprint
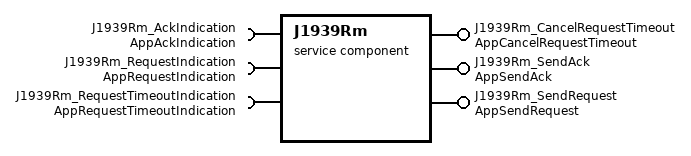
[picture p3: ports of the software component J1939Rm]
  service sw component type J1939Rm
    require port J1939Rm_AckIndication: variation-point=blueprint-condition=p=l-1={ecuc(J1939Rm/J1939RmGeneral.J1939RmSupportAckIndication)} == true, required-interface=AppAckIndication
    provide port J1939Rm_CancelRequestTimeout: variation-point=blueprint-condition=p=l-1={ecuc(J1939Rm/J1939RmGeneral.J1939RmSupportTimeoutSupervision)} == true, provided-interface=AppCancelRequestTimeout
    require port J1939Rm_RequestIndication: variation-point=blueprint-condition=p=l-1={ecuc(J1939Rm/J1939RmGeneral.J1939RmSupportRequestIndication)} == true, required-interface=AppRequestIndication
    require port J1939Rm_RequestTimeoutIndication: variation-point=blueprint-condition=p=l-1={ecuc(J1939Rm/J1939RmGeneral.J1939RmSupportTimeoutSupervision)} == true, required-interface=AppRequestTimeoutIndication
    provide port J1939Rm_SendAck: variation-point=blueprint-condition=p=l-1={ecuc(J1939Rm/J1939RmGeneral.J1939RmSupportAckTransmission)} == true, provided-interface=AppSendAck
    provide port J1939Rm_SendRequest: variation-point=blueprint-condition=p=l-1={ecuc(J1939Rm/J1939RmGeneral.J1939RmSupportRequestTransmission)} == true, provided-interface=AppSendRequest
    behavior J1939RmInternalBehavior
      port-api-options:
        {port-defined-argument-value{value=undefined, value-type=uint8}, port=J1939Rm_CancelRequestTimeout}
        {port-defined-argument-value{value=undefined, value-type=uint8}, port=J1939Rm_SendAck}
        {port-defined-argument-value{value=undefined, value-type=uint8}, port=J1939Rm_SendRequest}
package /AUTOSAR/SecOC/ClientServerInterfaces_Blueprint
  client server interface FreshnessManagement: is-service=true  # Freshness Management for SecOC
    5 x operation:
      GetRxFreshness: possible-error=[FreshnessManagement/E_OK, FreshnessManagement/E_NOT_OK, E_BUSY], variation-point=blueprint-condition=p=l-1=({ecuc(SecOC/SecOCRxPduProcessing/SecOCUseAuthDataFreshness)} == FALSE)  # This interface is used by the SecOC to obtain the current freshness value. This operation provides also a part of the Authentic-PDU data if configured.
        6 x arg:
          freshnessValueId: type=uint16, direction=IN  # Identifier of the freshness
          truncatedFreshnessValue: type=SecOC_FreshnessArrayType, direction=IN  # The truncated freshness value from the received Secured-IPDU
          truncatedFreshnessValueLength: type=uint32, direction=IN  # Length in bits of the truncated freshness value
          authVerifyAttempts: type=uint16, direction=IN  # The number of authentication verify attempts for the current PDU
          freshnessValue: type=SecOC_FreshnessArrayType, direction=OUT  # The freshness value for this PDU
          freshnessValueLength: type=uint32, direction=INOUT  # The freshness value length in bits.
      GetRxFreshnessAuthData: possible-error=[FreshnessManagement/E_OK, FreshnessManagement/E_NOT_OK, E_BUSY], variation-point=blueprint-condition=p=l-1=({ecuc(SecOC/SecOCRxPduProcessing/SecOCUseAuthDataFreshness)} == TRUE)  # This interface is used by the SecOC to obtain the current freshness value. This operation provides also a part of the Authentic-PDU data if configured.
        8 x arg:
          freshnessValueId: type=uint16, direction=IN  # Identifier of the freshness
          truncatedFreshnessValue: type=SecOC_FreshnessArrayType, direction=IN  # The truncated freshness value from the received Secured-IPDU
          truncatedFreshnessValueLength: type=uint32, direction=IN  # Length in bits of the truncated freshness value
          authenticDataFreshnessValue: type=SecOC_FreshnessArrayType, direction=IN  # The selected part of the authentic data.
          authenticDataFreshnessValueLength: type=uint16, direction=IN  # The length in bits of the authentic data part.
          authVerifyAttempts: type=uint16, direction=IN  # The number of authentication verify attempts for this PDU
          freshnessValue: type=SecOC_FreshnessArrayType, direction=OUT  # The freshness value for this PDU
          freshnessValueLength: type=uint32, direction=INOUT  # The freshness value length in bits.
      GetTxFreshness: possible-error=[FreshnessManagement/E_OK, FreshnessManagement/E_NOT_OK, E_BUSY], variation-point=blueprint-condition=p=l-1=({ecuc(SecOC/SecOCTxPduProcessing/SecOCProvideTxTruncatedFreshnessValue)} == FALSE)  # Returns the freshness value from the Most Significant Bits in the first byte in the array (SecOCFreshnessValue), in big endian format.
        arg freshnessValueId: type=uint16, direction=IN  # Identifier of the freshness
        arg freshnessValue: type=SecOC_FreshnessArrayType, direction=OUT  # Freshness value
        arg freshnessValueLength: type=uint32, direction=INOUT  # Length in bits of the freshness value
      GetTxFreshnessTruncData: possible-error=[FreshnessManagement/E_OK, FreshnessManagement/E_NOT_OK, E_BUSY], variation-point=blueprint-condition=p=l-1=({ecuc(SecOC/SecOCTxPduProcessing/SecOCProvideTxTruncatedFreshnessValue)} == TRUE)  # This operation is used by the SecOC to obtain the freshness that corresponds to the freshnessValueId. The operation provides the freshness and also the truncated freshness that shall be placed into the Secured-IPDU.
        5 x arg:
          freshnessValueId: type=uint16, direction=IN  # Identifier of the freshness
          freshnessValue: type=SecOC_FreshnessArrayType, direction=OUT  # Freshness value
          freshnessValueLength: type=uint32, direction=INOUT  # Length in bits of the freshness value
          truncatedFreshnessValue: type=SecOC_FreshnessArrayType, direction=OUT  # The truncated freshness value that has to be placed into the Secured-IPDU
          truncatedFreshnessValueLength: type=uint32, direction=INOUT  # The length in bits for the truncated freshness.
      SPduTxConfirmation: possible-error=FreshnessManagement/E_OK  # This operation is used by the SecOC to indicate that the Secured I-PDU has been initiated for transmission.
        arg freshnessValueId: type=uint16, direction=IN  # Identifier of the freshness
    error E_OK: error-code=0  # Operation successful
    error E_NOT_OK: error-code=1  # Operation failed
    error E_BUSY: error-code=2  # Operation temporary failed, a freshness cannot be provided at the moment.
  client server interface SendDefaultAuthenticationInformation: variation-point={short-label=SendDefaultAuthenticationInformation, blueprint-condition=p=l-1=({ecuc(SecOC/SecOCGeneral/SecOCDefaultAuthenticationInformationPattern.value != NULL)})}, is-service=true  # Sending Default Authentication Information configuration service.
    operation SendDefaultAuthenticationInformation: possible-error=[SendDefaultAuthenticationInformation/E_OK, SendDefaultAuthenticationInformation/E_NOT_OK], variation-point=blueprint-condition=p=l-1=({ecuc(SecOC/SecOCRxPduProcessing/SecOCUseAuthDataFreshness)} == FALSE)  # The service provides the ability to enable the sending of un-authenticated PDU to lower layer. (example: in case authentication build counter has reached the configuration value SecOCAuthenticationBuildAttempts or the query of the freshness function returns E_NOT_OK or the calculation of the authenticator has returned a non-recoverable error such as returning E_NOT_OK or KEY_FAILURE). This service is optional (the service is available only if SecOCDefaultAuthenticationInformationPattern is configured). If the service is not available or the service is available but the service was called with sendDefaultAuthenticationInformation as FALSE for a given FreshnessValueID , SecOC module shall remove the Authentic I-PDU from its internal buffer and cancel the transmission request in case the building of authentication Information failed. If the service is available and the service was called with sendDefaultAuthenticationInformation as TRUE for a given FreshnessValueID , SecOc will use SecOCDefaultAuthenticationInformationPattern as authentication Information and will not cancel the transmission request.
      arg FreshnessValueID: type=uint16, direction=IN  # ID of the Freshness Value for which sending SecOCDefaultAuthenticationInformationPattern should be enabled.
      arg sendDefaultAuthenticationInformation: type=boolean, direction=IN  # FALSE - sending SecOCDefaultAuthenticationInformationPattern shall be disabled for given FreshnessValueID TRUE - sending SecOCDefaultAuthenticationInformationPattern shall be enabled for given FreshnessValueID
    error E_OK: error-code=0  # Operation successful
    error E_NOT_OK: error-code=1  # Operation failed
  client server interface VerifyStatusConfiguration: is-service=true  # Verify Status Configuration Service of SecOC
    operation VerifyStatusOverride: possible-error=[VerifyStatusConfiguration/E_OK, VerifyStatusConfiguration/E_NOT_OK]  # This service provides the ability to force specific behaviour of SecOc: accept or drop an I-PDU with or without performing the verification of authenticator or independent of the authenticator verification result, and to force a specific result for SecOC_VerificationResultType allowing additional fault handling in the application. Option SECOC_OVERRIDE_PASS_UNTIL_NOTICE, SECOC_OVERRIDE_SKIP_UNTIL_LIMIT or SECOC_OVERRIDE_PASS_UNTIL_LIMIT are available only if SecOCEnableForcedPassOverride is set to TRUE.
      arg ValueId: type=uint16, direction=IN  # Identifier of the Value ID where override shall be applied to. If configuration option SecOCOverrideStatusWithDataId is set to TRUE, this value shall provide the DataID of the secured I-PDU. If SecOCOverrideStatusWithDataId is set to FALSE, this parameter shall provide the freshness value ID.
      arg overrideStatus: type=SecOC_OverrideStatusType, direction=IN  # Defines whether verification is executed and whether the I-PDU is passed on, and for how long the override is active.
      arg numberOfMessagesToOverride: type=uint8, direction=IN  # Number of sequential VerifyStatus to override when using a specific counter for authentication verification. This is only considered when OverrideStatus is equal to SECOC_OVERRIDE_DROP_UNTIL_LIMIT, SECOC_OVERRIDE_SKIP_UNTIL_LIMIT or SECOC_OVERRIDE_PASS_UNTIL_LIMIT.
    error E_OK: error-code=0  # Operation successful
    error E_NOT_OK: error-code=1  # Operation failed
package /AUTOSAR/SecOC/SenderReceiverInterfaces_Blueprint
  sender receiver interface VerificationStatus: is-service=true  # This service realizes a notification service that is used to propagate the status of each authentication attempt from the SecOC module to the application layer. This service can be configured such that: - Only "False" Verification Status is propagated to the application layer - Both "True" and "False" Verification Status are propagated to the application layer - No Verification Status is propagated to the application layer
    data verificationStatus: implementation-data-type=SecOC_VerificationStatusType
package /AUTOSAR/SecOC/ServiceSwComponentTypes_Blueprint
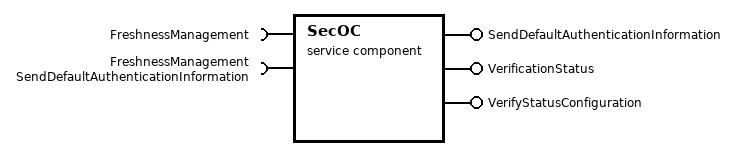
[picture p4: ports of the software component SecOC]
  service sw component type SecOC
    require port FreshnessManagement: variation-point=blueprint-condition=p=l-1=({ecuc(SecOC/SecOCGeneral/SecOCQueryFreshnessValue)} == RTE), required-interface=FreshnessManagement  # Port for the provision of freshness for SecOC.
    require port FreshnessManagement: variation-point=blueprint-condition=p=l-1=({ecuc(SecOC/SecOCGeneral/SecOCQueryFreshnessValue)} == RTE), required-interface=SendDefaultAuthenticationInformation  # Port for the provision of freshness for SecOC.
    provide port SendDefaultAuthenticationInformation: variation-point=blueprint-condition=p=l-1=({ecuc(SecOC/SecOCGeneral/SecOCDefaultAuthenticationInformationPattern.value != NULL)}), provided-interface=SendDefaultAuthenticationInformation
    provide port VerificationStatus: provided-interface=VerificationStatus
    provide port VerifyStatusConfiguration: provided-interface=VerifyStatusConfiguration
    behavior SecOCInternalBehavior
package /AUTOSAR/Dcm/ClientServerInterfaces_Blueprint
  13 x client server interface, all with is-service=true:
    Authentication
      operation SetDeauthenticatedRole: possible-error=Authentication/E_OK  # Sets a new role used in deauthenticated state for that connection. The set role is valid until the connection switches into authenticated state or the ECU is reset.
        arg deauthenticatedRole: type=Dcm_AuthenticationRoleType, direction=IN  # New deauthenticated role that is assigned to that connection.
      error E_OK: error-code=0  # Operation successful
    CallbackDCMRequestServices
      operation StartProtocol: possible-error=[CallbackDCMRequestServices/E_OK, CallbackDCMRequestServices/E_NOT_OK, E_PROTOCOL_NOT_ALLOWED]
        arg ProtocolType: type=Dcm_ProtocolType, direction=IN
        arg TesterSourceAddress: type=uint16, direction=IN
        arg ConnectionId: type=uint16, direction=IN
      operation StopProtocol: possible-error=[CallbackDCMRequestServices/E_OK, CallbackDCMRequestServices/E_NOT_OK]
        arg ProtocolType: type=Dcm_ProtocolType, direction=IN
        arg TesterSourceAddress: type=uint16, direction=IN
        arg ConnectionId: type=uint16, direction=IN
      error E_OK: error-code=0  # Operation successful
      error E_NOT_OK: error-code=1  # Operation failed
      error E_PROTOCOL_NOT_ALLOWED: error-code=5  # conditions in application allows no further procession of protocol
    DataServices_DIDRange: variation-point={short-label=DataServices_DIDRange, blueprint-condition=p=l-1={ecuc(Dcm/DcmConfigSet/DcmDsp/DcmDspDidRange.DcmDspDidRangeUsePort)} == TRUE}
      4 x operation:
        IsDidAvailable: possible-error=[DataServices_DIDRange/E_OK, DataServices_DIDRange/DCM_E_PENDING], variation-point=blueprint-condition=p=l-1={ecuc(Dcm/DcmConfigSet/DcmDsp/DcmDspDidRange.DcmDspDidRangeHasGaps)} == TRUE
          arg DID: type=uint16, direction=IN
          arg OpStatus: type=Dcm_OpStatusType, direction=IN
          arg supported: type=Dcm_DidSupportedType, direction=OUT
        ReadDidData: possible-error=[DataServices_DIDRange/E_OK, DataServices_DIDRange/E_NOT_OK, DataServices_DIDRange/DCM_E_PENDING], variation-point=blueprint-condition=p=l-1=({ecuc(Dcm/DcmConfigSet/DcmDsp/DcmDspDidRange/DcmDspDidRangeInfoRef->DcmDspDidRead)} != NULL)
          5 x arg:
            DID: type=uint16, direction=IN
            Data: type=Dcm_RangeArrayType, direction=OUT
            OpStatus: type=Dcm_OpStatusType, direction=IN
            DataLength: type=uint16, direction=OUT
            ErrorCode: type=Dcm_NegativeResponseCodeType, direction=OUT
        ReadDidRangeDataLength: possible-error=[DataServices_DIDRange/E_OK, DataServices_DIDRange/E_NOT_OK, DataServices_DIDRange/DCM_E_PENDING], variation-point=blueprint-condition=p=l-1=({ecuc(Dcm/DcmConfigSet/DcmDsp/DcmDspDidRange/DcmDspDidRangeInfoRef->DcmDspDidRead)} != NULL)
          arg DID: type=uint16, direction=IN
          arg OpStatus: type=Dcm_OpStatusType, direction=IN
          arg DataLength: type=uint16, direction=OUT
        WriteDidData: possible-error=[DataServices_DIDRange/E_OK, DataServices_DIDRange/E_NOT_OK, DataServices_DIDRange/DCM_E_PENDING], variation-point=blueprint-condition=p=l-1=({ecuc(Dcm/DcmConfigSet/DcmDsp/DcmDspDidRange/DcmDspDidRangeInfoRef->DcmDspDidWrite)} != NULL)
          5 x arg:
            DID: type=uint16, direction=IN
            Data: type=Dcm_RangeArrayType, direction=IN
            OpStatus: type=Dcm_OpStatusType, direction=IN
            DataLength: type=uint16, direction=IN
            ErrorCode: type=Dcm_NegativeResponseCodeType, direction=OUT
      error E_OK: error-code=0  # Operation successful
      error E_NOT_OK: error-code=1  # Operation failed
      error DCM_E_PENDING: error-code=10  # Request is not yet finished. Further call(s) required to finish.
    DataServices: variation-point={short-label=DataServicesCS, blueprint-condition=p=l-1=((( {ecuc(Dcm/DcmConfigSet/DcmDsp/DcmDspDid/DcmDspDidUsePort)} == USE_DATA_ELEMENT_SPECIFIC_INTERFACES)) || ({ecuc(Dcm/DcmConfigSet/DcmDsp/DcmDspData.DcmDspDataUsePort)} == USE_DATA_SYNCH_CLIENT_SERVER) || ({ecuc(Dcm/DcmConfigSet/DcmDsp/DcmDspData.DcmDspDataUsePort)} ==USE_DATA_ASYNCH_CLIENT_SERVER) || ({ecuc(Dcm/cmConfigSet/DcmDsp/DcmDspData.DcmDspDataUsePort)} ==USE_DATA_ASYNCH_CLIENT_SERVER_ERROR) || ({ecuc(Dcm/DcmConfigSet/DcmDsp/DcmDspPid/DcmDspPidData/DcmDspPidService01.DcmDspPidDataUsePort)} ==USE_DATA_SYNCH_CLIENT_SERVER) )}
      31 x operation:
        ConditionCheckRead: possible-error=[DataServices/E_OK, DataServices/E_NOT_OK, DataServices/DCM_E_PENDING], variation-point=blueprint-condition=p=l-1=({ecuc(Dcm/DcmConfigSet/DcmDsp/DcmDspData.DcmDspDataUsePort)} == (USE_DATA_ASYNCH_CLIENT_SERVER || USE_DATA_ASYNCH_CLIENT_SERVER_ERROR)) && ({ecuc(Dcm/DcmConfigSet/DcmDsp/DcmDspDidInfo/DcmDspDidRead)} != NULL) && ({ecuc(Dcm/DcmConfigSet/DcmDsp/DcmDspData.DcmDspDataConditionCheckReadFncUsed)} == TRUE)
          arg OpStatus: type=Dcm_OpStatusType, direction=IN
          arg ErrorCode: type=Dcm_NegativeResponseCodeType, direction=OUT
        ConditionCheckRead: possible-error=[DataServices/E_OK, DataServices/E_NOT_OK], variation-point=blueprint-condition=p=l-1=({ecuc(Dcm/DcmConfigSet/DcmDsp/DcmDspData.DcmDspDataUsePort)} == USE_DATA_SYNCH_CLIENT_SERVER) && ({ecuc(Dcm/DcmConfigSet/DcmDsp/DcmDspDidInfo/DcmDspDidRead)} != NULL) && ({ecuc(Dcm/DcmConfigSet/DcmDsp/DcmDspData.DcmDspDataConditionCheckReadFncUsed)} == TRUE)
          arg ErrorCode: type=Dcm_NegativeResponseCodeType, direction=OUT
        FreezeCurrentState: possible-error=[DataServices/E_OK, DataServices/E_NOT_OK, DataServices/DCM_E_PENDING], variation-point=blueprint-condition=p=l-1=({ecuc(Dcm/DcmConfigSet/DcmDsp/DcmDspData.DcmDspDataUsePort)} == (USE_DATA_ASYNCH_CLIENT_SERVER || USE_DATA_ASYNCH_CLIENT_SERVER_ERROR)) && ({ecuc(Dcm/DcmConfigSet/DcmDsp/DcmDspDidInfo/DcmDspDidControl/DcmDspDidFreezeCurrentState)} == TRUE) && ({ecuc(Dcm/DcmConfigSet/DcmDsp/DcmDspDid/DcmDspDidInfoRef->DcmDspDidInfo/DcmDspDidControl/DcmDspDidControlMask)} != DCM_CONTROLMASK_EXTERNAL)
          arg OpStatus: type=Dcm_OpStatusType, direction=IN
          arg ErrorCode: type=Dcm_NegativeResponseCodeType, direction=OUT
        FreezeCurrentState: possible-error=[DataServices/E_OK, DataServices/E_NOT_OK, DataServices/DCM_E_PENDING], variation-point=blueprint-condition=p=l-1=({ecuc(Dcm/DcmConfigSet/DcmDsp/DcmDspData.DcmDspDataUsePort)} == (USE_DATA_ASYNCH_CLIENT_SERVER || USE_DATA_ASYNCH_CLIENT_SERVER_ERROR)) && ({ecuc(Dcm/DcmConfigSet/DcmDsp/DcmDspDidInfo/DcmDspDidControl/DcmDspDidFreezeCurrentState)} == TRUE) && ({ecuc(Dcm/DcmConfigSet/DcmDsp/DcmDspDid/DcmDspDidInfoRef->DcmDspDidInfo/DcmDspDidControl/DcmDspDidControlMask)} == DCM_CONTROLMASK_EXTERNAL)
          arg OpStatus: type=Dcm_OpStatusType, direction=IN
          arg controlMask: type=Dcm_ControlMaskType, direction=IN
          arg ErrorCode: type=Dcm_NegativeResponseCodeType, direction=OUT
        FreezeCurrentState: possible-error=[DataServices/E_OK, DataServices/E_NOT_OK], variation-point=blueprint-condition=p=l-1=({ecuc(Dcm/DcmConfigSet/DcmDsp/DcmDspData.DcmDspDataUsePort)} == USE_DATA_SYNCH_CLIENT_SERVER) && ({ecuc(Dcm/DcmConfigSet/DcmDsp/DcmDspDidInfo/DcmDspDidControl/DcmDspDidFreezeCurrentState)} == TRUE) && ({ecuc(Dcm/DcmConfigSet/DcmDsp/DcmDspDid/DcmDspDidInfoRef->DcmDspDidInfo/DcmDspDidControl/DcmDspDidControlMask)} != DCM_CONTROLMASK_EXTERNAL)
          arg ErrorCode: type=Dcm_NegativeResponseCodeType, direction=OUT
        FreezeCurrentState: possible-error=[DataServices/E_OK, DataServices/E_NOT_OK], variation-point=blueprint-condition=p=l-1=({ecuc(Dcm/DcmConfigSet/DcmDsp/DcmDspData.DcmDspDataUsePort)} == USE_DATA_SYNCH_CLIENT_SERVER) && ({ecuc(Dcm/DcmConfigSet/DcmDsp/DcmDspDidInfo/DcmDspDidControl/DcmDspDidFreezeCurrentState)} == TRUE) && ({ecuc(Dcm/DcmConfigSet/DcmDsp/DcmDspDid/DcmDspDidInfoRef->DcmDspDidInfo/DcmDspDidControl/DcmDspDidControlMask)} == DCM_CONTROLMASK_EXTERNAL)
          arg controlMask: type=Dcm_ControlMaskType, direction=IN
          arg ErrorCode: type=Dcm_NegativeResponseCodeType, direction=OUT
        GetScalingInformation: possible-error=[DataServices/E_OK, DataServices/E_NOT_OK, DataServices/DCM_E_PENDING], variation-point=blueprint-condition=p=l-1=({ecuc(Dcm/DcmConfigSet/DcmDsp/DcmDspData.DcmDspDataUsePort)} == (USE_DATA_ASYNCH_CLIENT_SERVER || USE_DATA_ASYNCH_CLIENT_SERVER_ERROR)) && ({ecuc(Dcm/DcmConfigSet/DcmDsp/DcmDspData/DcmDspDataInfoRef->DcmDspDataScalingInfoSize)} != NULL)
          arg OpStatus: type=Dcm_OpStatusType, direction=IN
          arg ScalingInfo: type=Dcm_ScalingInfoArrayType, direction=OUT
          arg ErrorCode: type=Dcm_NegativeResponseCodeType, direction=OUT
        GetScalingInformation: possible-error=[DataServices/E_OK, DataServices/E_NOT_OK], variation-point=blueprint-condition=p=l-1=({ecuc(Dcm/DcmConfigSet/DcmDsp/DcmDspData.DcmDspDataUsePort)} == USE_DATA_SYNCH_CLIENT_SERVER) && ({ecuc(Dcm/DcmConfigSet/DcmDsp/DcmDspData/DcmDspDataInfoRef->DcmDspDataScalingInfoSize)} != NULL)
          arg ScalingInfo: type=Dcm_ScalingInfoArrayType, direction=OUT
          arg ErrorCode: type=Dcm_NegativeResponseCodeType, direction=OUT
        ReadData: possible-error=[DataServices/E_OK, DataServices/E_NOT_OK, DataServices/DCM_E_PENDING], variation-point=blueprint-condition=p=l-1=({ecuc(Dcm/DcmConfigSet/DcmDsp/DcmDspData.DcmDspDataUsePort)} == USE_DATA_ASYNCH_CLIENT_SERVER) && ({ecuc(Dcm/DcmConfigSet/DcmDsp/DcmDspDidInfo/DcmDspDidRead)} != NULL)
          arg OpStatus: type=Dcm_OpStatusType, direction=IN
          arg Data: type=Dcm_DataElementType, direction=OUT
        ReadData: possible-error=[DataServices/E_OK, DataServices/E_NOT_OK, DataServices/DCM_E_PENDING], variation-point=blueprint-condition=p=l-1=({ecuc(Dcm/DcmConfigSet/DcmDsp/DcmDspData.DcmDspDataUsePort)} == USE_DATA_ASYNCH_CLIENT_SERVER_ERROR) && ({ecuc(Dcm/DcmConfigSet/DcmDsp/DcmDspDidInfo/DcmDspDidRead)} != NULL)
          arg OpStatus: type=Dcm_OpStatusType, direction=IN
          arg Data: type=Dcm_DataElementType, direction=OUT
          arg ErrorCode: type=Dcm_NegativeResponseCodeType, direction=OUT
        ReadData: possible-error=[DataServices/E_OK, DataServices/E_NOT_OK], variation-point=blueprint-condition=p=l-1=({ecuc(Dcm/DcmConfigSet/DcmDsp/DcmDspData.DcmDspDataUsePort)} == USE_DATA_SYNCH_CLIENT_SERVER) && (({ecuc(Dcm/DcmConfigSet/DcmDsp/DcmDspDidInfo/DcmDspDidRead)} != NULL) || ({ecuc(Dcm/DcmConfigSet/DcmDsp/DcmDspPid/DcmDspPidData/DcmDspPidService01.DcmDspPidDataUsePort)} == USE_DATA_SYNCH_CLIENT_SERVER))
          arg Data: type=Dcm_DataElementType, direction=OUT
        ReadDataLength: possible-error=[DataServices/E_OK, DataServices/E_NOT_OK, DataServices/DCM_E_PENDING], variation-point=blueprint-condition=p=l-1=({ecuc(Dcm/DcmConfigSet/DcmDsp/DcmDspData.DcmDspDataUsePort)} == (USE_DATA_ASYNCH_CLIENT_SERVER || USE_DATA_ASYNCH_CLIENT_SERVER_ERROR)) && ({ecuc(Dcm/DcmConfigSet/DcmDsp/DcmDspDidInfo/DcmDspDidRead)} != NULL) && ({ecuc(Dcm/DcmConfigSet/DcmDsp/DcmDspData.DcmDspDataType} == UINT8_DYN)
          arg OpStatus: type=Dcm_OpStatusType, direction=IN
          arg DataLength: type=uint16, direction=OUT
        ReadDataLength: possible-error=[DataServices/E_OK, DataServices/E_NOT_OK], variation-point=blueprint-condition=p=l-1=({ecuc(Dcm/DcmConfigSet/DcmDsp/DcmDspData.DcmDspDataUsePort)} == USE_DATA_SYNCH_CLIENT_SERVER) && ({ecuc(Dcm/DcmConfigSet/DcmDsp/DcmDspDidInfo/DcmDspDidRead)} != NULL) && ({ecuc(Dcm/DcmConfigSet/DcmDsp/DcmDspData.DcmDspDataType} == UINT8_DYN)
          arg DataLength: type=uint16, direction=OUT
        ResetToDefault: possible-error=[DataServices/E_OK, DataServices/E_NOT_OK, DataServices/DCM_E_PENDING], variation-point=blueprint-condition=p=l-1=({ecuc(Dcm/DcmConfigSet/DcmDsp/DcmDspData.DcmDspDataUsePort)} == (USE_DATA_ASYNCH_CLIENT_SERVER || USE_DATA_ASYNCH_CLIENT_SERVER_ERROR)) && ({ecuc(Dcm/DcmConfigSet/DcmDsp/DcmDspDidInfo/DcmDspDidControl/DcmDspDidResetToDefault)} == TRUE) && ({ecuc(Dcm/DcmConfigSet/DcmDsp/DcmDspDid/DcmDspDidInfoRef->DcmDspDidInfo/DcmDspDidControl/DcmDspDidControlMask)} != DCM_CONTROLMASK_EXTERNAL)
          arg OpStatus: type=Dcm_OpStatusType, direction=IN
          arg ErrorCode: type=Dcm_NegativeResponseCodeType, direction=OUT
        ResetToDefault: possible-error=[DataServices/E_OK, DataServices/E_NOT_OK, DataServices/DCM_E_PENDING], variation-point=blueprint-condition=p=l-1=({ecuc(Dcm/DcmConfigSet/DcmDsp/DcmDspData.DcmDspDataUsePort)} == (USE_DATA_ASYNCH_CLIENT_SERVER || USE_DATA_ASYNCH_CLIENT_SERVER_ERROR)) && ({ecuc(Dcm/DcmConfigSet/DcmDsp/DcmDspDidInfo/DcmDspDidControl/DcmDspDidResetToDefault)} == TRUE) && ({ecuc(Dcm/DcmConfigSet/DcmDsp/DcmDspDid/DcmDspDidInfoRef->DcmDspDidInfo/DcmDspDidControl/DcmDspDidControlMask)} == DCM_CONTROLMASK_EXTERNAL)
          arg OpStatus: type=Dcm_OpStatusType, direction=IN
          arg controlMask: type=Dcm_ControlMaskType, direction=IN
          arg ErrorCode: type=Dcm_NegativeResponseCodeType, direction=OUT
        ResetToDefault: possible-error=[DataServices/E_OK, DataServices/E_NOT_OK], variation-point=blueprint-condition=p=l-1=({ecuc(Dcm/DcmConfigSet/DcmDsp/DcmDspData.DcmDspDataUsePort)} == USE_DATA_SYNCH_CLIENT_SERVER) && ({ecuc(Dcm/DcmConfigSet/DcmDsp/DcmDspDidInfo/DcmDspDidControl/DcmDspDidResetToDefault)} == TRUE) && ({ecuc(Dcm/DcmConfigSet/DcmDsp/DcmDspDid/DcmDspDidInfoRef->DcmDspDidInfo/DcmDspDidControl/DcmDspDidControlMask)} != DCM_CONTROLMASK_EXTERNAL)
          arg ErrorCode: type=Dcm_NegativeResponseCodeType, direction=OUT
        ResetToDefault: possible-error=[DataServices/E_OK, DataServices/E_NOT_OK], variation-point=blueprint-condition=p=l-1=({ecuc(Dcm/DcmConfigSet/DcmDsp/DcmDspData.DcmDspDataUsePort)} == USE_DATA_SYNCH_CLIENT_SERVER) && ({ecuc(Dcm/DcmConfigSet/DcmDsp/DcmDspDidInfo/DcmDspDidControl/DcmDspDidResetToDefault)} == TRUE) && ({ecuc(Dcm/DcmConfigSet/DcmDsp/DcmDspDid/DcmDspDidInfoRef->DcmDspDidInfo/DcmDspDidControl/DcmDspDidControlMask)} == DCM_CONTROLMASK_EXTERNAL)
          arg controlMask: type=Dcm_ControlMaskType, direction=IN
          arg ErrorCode: type=Dcm_NegativeResponseCodeType, direction=OUT
        ReturnControlToECU: possible-error=[DataServices/E_OK, DataServices/E_NOT_OK], variation-point=blueprint-condition=p=l-1=({ecuc(Dcm/DcmConfigSet/DcmDsp/DcmDspData.DcmDspDataUsePort)} == (USE_DATA_SYNCH_CLIENT_SERVER || USE_DATA_ASYNCH_CLIENT_SERVER || USE_DATA_ASYNCH_CLIENT_SERVER_ERROR)) && ({ecuc(Dcm/DcmConfigSet/DcmDsp/DcmDspDidInfo/DcmDspDidControl/DcmDspDidFreezeCurrentState)} == TRUE) || ({ecuc(Dcm/DcmConfigSet/DcmDsp/DcmDspDidInfo/DcmDspDidControl/DcmDspDidResetToDefault)} == TRUE) || ({ecuc(Dcm/DcmConfigSet/DcmDsp/DcmDspDidInfo/DcmDspDidControl/DcmDspDidShortTermAdjustment)} == TRUE) && ({ecuc(Dcm/DcmConfigSet/DcmDsp/DcmDspDid/DcmDspDidInfoRef->DcmDspDidInfo/DcmDspDidControl/DcmDspDidControlMask)} != DCM_CONTROLMASK_EXTERNAL)
          arg ErrorCode: type=Dcm_NegativeResponseCodeType, direction=OUT
        ReturnControlToECU: possible-error=[DataServices/E_OK, DataServices/E_NOT_OK], variation-point=blueprint-condition=p=l-1=({ecuc(Dcm/DcmConfigSet/DcmDsp/DcmDspDidInfo/DcmDspDidControl/DcmDspDidFreezeCurrentState)} == TRUE) || ({ecuc(Dcm/DcmConfigSet/DcmDsp/DcmDspDidInfo/DcmDspDidControl/DcmDspDidResetToDefault)} == TRUE) || ({ecuc(Dcm/DcmConfigSet/DcmDsp/DcmDspDidInfo/DcmDspDidControl/DcmDspDidShortTermAdjustment)} == TRUE) && ({ecuc(Dcm/DcmConfigSet/DcmDsp/DcmDspDid/DcmDspDidInfoRef->DcmDspDidInfo/DcmDspDidControl/DcmDspDidControlMask)} == DCM_CONTROLMASK_EXTERNAL)
          arg controlMask: type=Dcm_ControlMaskType, direction=IN
          arg ErrorCode: type=Dcm_NegativeResponseCodeType, direction=OUT
        ShortTermAdjustment: possible-error=[DataServices/E_OK, DataServices/E_NOT_OK, DataServices/DCM_E_PENDING], variation-point=blueprint-condition=p=l-1=({ecuc(Dcm/DcmConfigSet/DcmDsp/DcmDspData.DcmDspDataUsePort)} == (USE_DATA_ASYNCH_CLIENT_SERVER || USE_DATA_ASYNCH_CLIENT_SERVER_ERROR)) && ({ecuc(Dcm/DcmConfigSet/DcmDsp/DcmDspDidInfo/DcmDspDidControl/DcmDspDidShortTermAdjustment)} == TRUE) && ({ecuc(Dcm/DcmConfigSet/DcmDsp/DcmDspData.DcmDspDataType} != UINT8_DYN) && ({ecuc(Dcm/DcmConfigSet/DcmDsp/DcmDspDid/DcmDspDidInfoRef->DcmDspDidInfo/DcmDspDidControl/DcmDspDidControlMask)} != DCM_CONTROLMASK_EXTERNAL)
          arg ControlStateInfo: type=Dcm_DataArrayTypeUint8Type, direction=IN
          arg OpStatus: type=Dcm_OpStatusType, direction=IN
          arg ErrorCode: type=Dcm_NegativeResponseCodeType, direction=OUT
        ShortTermAdjustment: possible-error=[DataServices/E_OK, DataServices/E_NOT_OK, DataServices/DCM_E_PENDING], variation-point=blueprint-condition=p=l-1=({ecuc(Dcm/DcmConfigSet/DcmDsp/DcmDspData.DcmDspDataUsePort)} == (USE_DATA_ASYNCH_CLIENT_SERVER || USE_DATA_ASYNCH_CLIENT_SERVER_ERROR)) && ({ecuc(Dcm/DcmConfigSet/DcmDsp/DcmDspDidInfo/DcmDspDidControl/DcmDspDidShortTermAdjustment)} == TRUE) && ({ecuc(Dcm/DcmConfigSet/DcmDsp/DcmDspData.DcmDspDataType} != UINT8_DYN) && ({ecuc(Dcm/DcmConfigSet/DcmDsp/DcmDspDid/DcmDspDidInfoRef->DcmDspDidInfo/DcmDspDidControl/DcmDspDidControlMask)} == DCM_CONTROLMASK_EXTERNAL)
          4 x arg:
            ControlStateInfo: type=Dcm_DataArrayTypeUint8Type, direction=IN
            OpStatus: type=Dcm_OpStatusType, direction=IN
            controlMask: type=Dcm_ControlMaskType, direction=IN
            ErrorCode: type=Dcm_NegativeResponseCodeType, direction=OUT
        ShortTermAdjustment: possible-error=[DataServices/E_OK, DataServices/E_NOT_OK, DataServices/DCM_E_PENDING], variation-point=blueprint-condition=p=l-1=({ecuc(Dcm/DcmConfigSet/DcmDsp/DcmDspData.DcmDspDataUsePort)} == (USE_DATA_ASYNCH_CLIENT_SERVER || USE_DATA_ASYNCH_CLIENT_SERVER_ERROR)) && ({ecuc(Dcm/DcmConfigSet/DcmDsp/DcmDspDidInfo/DcmDspDidControl/DcmDspDidShortTermAdjustment)} == TRUE) && ({ecuc(Dcm/DcmConfigSet/DcmDsp/DcmDspData.DcmDspDataType} == UINT8_DYN) &&({ecuc(Dcm/DcmConfigSet/DcmDsp/DcmDspDid/DcmDspDidInfoRef->DcmDspDidInfo/DcmDspDidControl/DcmDspDidControlMask)} != DCM_CONTROLMASK_EXTERNAL)
          4 x arg:
            ControlStateInfo: type=Dcm_DataArrayTypeUint8Type, direction=IN
            DataLength: type=uint16, direction=IN
            OpStatus: type=Dcm_OpStatusType, direction=IN
            ErrorCode: type=Dcm_NegativeResponseCodeType, direction=OUT
        ShortTermAdjustment: possible-error=[DataServices/E_OK, DataServices/E_NOT_OK, DataServices/DCM_E_PENDING], variation-point=blueprint-condition=p=l-1=({ecuc(Dcm/DcmConfigSet/DcmDsp/DcmDspData.DcmDspDataUsePort)} == (USE_DATA_ASYNCH_CLIENT_SERVER || USE_DATA_ASYNCH_CLIENT_SERVER_ERROR)) && ({ecuc(Dcm/DcmConfigSet/DcmDsp/DcmDspDidInfo/DcmDspDidControl/DcmDspDidShortTermAdjustment)} == TRUE) && ({ecuc(Dcm/DcmConfigSet/DcmDsp/DcmDspData.DcmDspDataType} == UINT8_DYN) && ({ecuc(Dcm/DcmConfigSet/DcmDsp/DcmDspDid/DcmDspDidInfoRef->DcmDspDidInfo/DcmDspDidControl/DcmDspDidControlMask)} == DCM_CONTROLMASK_EXTERNAL)
          5 x arg:
            ControlStateInfo: type=Dcm_DataArrayTypeUint8Type, direction=IN
            DataLength: type=uint16, direction=IN
            OpStatus: type=Dcm_OpStatusType, direction=IN
            controlMask: type=Dcm_ControlMaskType, direction=IN
            ErrorCode: type=Dcm_NegativeResponseCodeType, direction=OUT
        ShortTermAdjustment: possible-error=[DataServices/E_OK, DataServices/E_NOT_OK], variation-point=blueprint-condition=p=l-1=({ecuc(Dcm/DcmConfigSet/DcmDsp/DcmDspData.DcmDspDataUsePort)} == USE_DATA_SYNCH_CLIENT_SERVER) && ({ecuc(Dcm/DcmConfigSet/DcmDsp/DcmDspDidInfo/DcmDspDidControl/DcmDspDidShortTermAdjustment)} == TRUE) && ({ecuc(Dcm/DcmConfigSet/DcmDsp/DcmDspData.DcmDspDataType} != UINT8_DYN) &&({ecuc(Dcm/DcmConfigSet/DcmDsp/DcmDspDid/DcmDspDidInfoRef->DcmDspDidInfo/DcmDspDidControl/DcmDspDidControlMask)} != DCM_CONTROLMASK_EXTERNAL)
          arg ControlStateInfo: type=Dcm_DataArrayTypeUint8Type, direction=IN
          arg ErrorCode: type=Dcm_NegativeResponseCodeType, direction=OUT
        ShortTermAdjustment: possible-error=[DataServices/E_OK, DataServices/E_NOT_OK], variation-point=blueprint-condition=p=l-1=({ecuc(Dcm/DcmConfigSet/DcmDsp/DcmDspData.DcmDspDataUsePort)} == USE_DATA_SYNCH_CLIENT_SERVER) && ({ecuc(Dcm/DcmConfigSet/DcmDsp/DcmDspDidInfo/DcmDspDidControl/DcmDspDidShortTermAdjustment)} == TRUE) && ({ecuc(Dcm/DcmConfigSet/DcmDsp/DcmDspData.DcmDspDataType} != UINT8_DYN) && ({ecuc(Dcm/DcmConfigSet/DcmDsp/DcmDspDid/DcmDspDidInfoRef->DcmDspDidInfo/DcmDspDidControl/DcmDspDidControlMask)} == DCM_CONTROLMASK_EXTERNAL)
          arg ControlStateInfo: type=Dcm_DataArrayTypeUint8Type, direction=IN
          arg controlMask: type=Dcm_ControlMaskType, direction=IN
          arg ErrorCode: type=Dcm_NegativeResponseCodeType, direction=OUT
        ShortTermAdjustment: possible-error=[DataServices/E_OK, DataServices/E_NOT_OK], variation-point=blueprint-condition=p=l-1=({ecuc(Dcm/DcmConfigSet/DcmDsp/DcmDspData.DcmDspDataUsePort)} == USE_DATA_SYNCH_CLIENT_SERVER) && ({ecuc(Dcm/DcmConfigSet/DcmDsp/DcmDspDidInfo/DcmDspDidControl/DcmDspDidShortTermAdjustment)} == TRUE) && ({ecuc(Dcm/DcmConfigSet/DcmDsp/DcmDspData.DcmDspDataType} == UINT8_DYN) &&({ecuc(Dcm/DcmConfigSet/DcmDsp/DcmDspDid/DcmDspDidInfoRef->DcmDspDidInfo/DcmDspDidControl/DcmDspDidControlMask)} != DCM_CONTROLMASK_EXTERNAL)
          arg ControlStateInfo: type=Dcm_DataArrayTypeUint8Type, direction=IN
          arg DataLength: type=uint16, direction=IN
          arg ErrorCode: type=Dcm_NegativeResponseCodeType, direction=OUT
        ShortTermAdjustment: possible-error=[DataServices/E_OK, DataServices/E_NOT_OK], variation-point=blueprint-condition=p=l-1=({ecuc(Dcm/DcmConfigSet/DcmDsp/DcmDspData.DcmDspDataUsePort)} == USE_DATA_SYNCH_CLIENT_SERVER) && ({ecuc(Dcm/DcmConfigSet/DcmDsp/DcmDspDidInfo/DcmDspDidControl/DcmDspDidShortTermAdjustment)} == TRUE) && ({ecuc(Dcm/DcmConfigSet/DcmDsp/DcmDspData.DcmDspDataType} == UINT8_DYN) && ({ecuc(Dcm/DcmConfigSet/DcmDsp/DcmDspDid/DcmDspDidInfoRef->DcmDspDidInfo/DcmDspDidControl/DcmDspDidControlMask)} == DCM_CONTROLMASK_EXTERNAL)
          4 x arg:
            ControlStateInfo: type=Dcm_DataArrayTypeUint8Type, direction=IN
            DataLength: type=uint16, direction=IN
            controlMask: type=Dcm_ControlMaskType, direction=IN
            ErrorCode: type=Dcm_NegativeResponseCodeType, direction=OUT
        WriteData: possible-error=[DataServices/E_OK, DataServices/E_NOT_OK, DataServices/DCM_E_PENDING], variation-point=blueprint-condition=p=l-1=({ecuc(Dcm/DcmConfigSet/DcmDsp/DcmDspData.DcmDspDataUsePort)} == (USE_DATA_ASYNCH_CLIENT_SERVER || USE_DATA_ASYNCH_CLIENT_SERVER_ERROR)) && ({ecuc(Dcm/DcmConfigSet/DcmDsp/DcmDspDidInfo/DcmDspDidWrite)} != NULL) && ({ecuc(Dcm/DcmConfigSet/DcmDsp/DcmDspData.DcmDspDataType} != UINT8_DYN)
          arg Data: type=Dcm_DataElementType, direction=IN
          arg OpStatus: type=Dcm_OpStatusType, direction=IN
          arg ErrorCode: type=Dcm_NegativeResponseCodeType, direction=OUT
        WriteData: possible-error=[DataServices/E_OK, DataServices/E_NOT_OK, DataServices/DCM_E_PENDING], variation-point=blueprint-condition=p=l-1=({ecuc(Dcm/DcmConfigSet/DcmDsp/DcmDspData.DcmDspDataUsePort)} == (USE_DATA_ASYNCH_CLIENT_SERVER || USE_DATA_ASYNCH_CLIENT_SERVER_ERROR)) && ({ecuc(Dcm/DcmConfigSet/DcmDsp/DcmDspDidInfo/DcmDspDidWrite)} != NULL) && ({ecuc(Dcm/DcmConfigSet/DcmDsp/DcmDspData.DcmDspDataType} == UINT8_DYN)
          4 x arg:
            Data: type=Dcm_DataElementType, direction=IN
            DataLength: type=uint16, direction=IN
            OpStatus: type=Dcm_OpStatusType, direction=IN
            ErrorCode: type=Dcm_NegativeResponseCodeType, direction=OUT
        WriteData: possible-error=[DataServices/E_OK, DataServices/E_NOT_OK], variation-point=blueprint-condition=p=l-1=({ecuc(Dcm/DcmConfigSet/DcmDsp/DcmDspData.DcmDspDataUsePort)} == USE_DATA_SYNCH_CLIENT_SERVER) && ({ecuc(Dcm/DcmConfigSet/DcmDsp/DcmDspDidInfo/DcmDspDidWrite)} != NULL) && ({ecuc(Dcm/DcmConfigSet/DcmDsp/DcmDspData.DcmDspDataType} != UINT8_DYN)
          arg Data: type=Dcm_DataElementType, direction=IN
          arg ErrorCode: type=Dcm_NegativeResponseCodeType, direction=OUT
        WriteData: possible-error=[DataServices/E_OK, DataServices/E_NOT_OK], variation-point=blueprint-condition=p=l-1=({ecuc(Dcm/DcmConfigSet/DcmDsp/DcmDspData.DcmDspDataUsePort)} == USE_DATA_SYNCH_CLIENT_SERVER) && ({ecuc(Dcm/DcmConfigSet/DcmDsp/DcmDspDidInfo/DcmDspDidWrite)} != NULL) && ({ecuc(Dcm/DcmConfigSet/DcmDsp/DcmDspData.DcmDspDataType} == UINT8_DYN)
          arg Data: type=Dcm_DataElementType, direction=IN
          arg DataLength: type=uint16, direction=IN
          arg ErrorCode: type=Dcm_NegativeResponseCodeType, direction=OUT
      error E_OK: error-code=0  # Operation successful
      error E_NOT_OK: error-code=1  # Operation failed
      error DCM_E_PENDING: error-code=10  # Request is not yet finished. Further call(s) required to finish.
    DCM_Roe: variation-point={short-label=DCM_Roe, blueprint-condition=p=l-1={ecuc(Dcm/DcmConfigSet/DcmDsp/DcmDspRoe/DcmDspRoeEvent)}}
      operation TriggerOnEvent: possible-error=[DCM_Roe/E_OK, DCM_Roe/E_NOT_OK]
      error E_OK: error-code=0  # Operation successful
      error E_NOT_OK: error-code=1  # Operation failed
    DCMServices
      5 x operation:
        GetActiveProtocol: possible-error=DCMServices/E_OK
          arg ActiveProtocolType: type=Dcm_ProtocolType, direction=OUT
          arg ConnectionId: type=uint16, direction=OUT
          arg TesterSourceAddress: type=uint16, direction=OUT
        GetSecurityLevel: possible-error=[DCMServices/E_OK, DCMServices/E_NOT_OK]
          arg SecLevel: type=Dcm_SecLevelType, direction=OUT
        GetSesCtrlType: possible-error=[DCMServices/E_OK, DCMServices/E_NOT_OK]
          arg SesCtrlType: type=Dcm_SesCtrlType, direction=OUT
        ResetToDefaultSession: possible-error=[DCMServices/E_OK, DCMServices/E_NOT_OK]
        SetActiveDiagnostic: possible-error=DCMServices/E_OK  # Allows to activate and deactivate the call of ComM_DCM_ActiveDiagnostic() function.
          arg active: type=boolean, direction=IN  # If false Dcm shall not call ComM_DCM_ActiveDiagnostic(). If true Dcm will call ComM_DCM_ActiveDiagnostic().
      error E_OK: error-code=0  # Operation successful
      error E_NOT_OK: error-code=1  # Operation failed
    InfotypeServices: variation-point={short-label=InfotypeServices, blueprint-condition=p=l-1={ecuc(Dcm/DcmConfigSet/DcmDsp/DcmDspVehInfo/DcmDspVehInfoData/DcmDspVehInfoDataUsePort)}==TRUE}
      operation GetInfotypeValueData: possible-error=[InfotypeServices/E_OK, InfotypeServices/E_NOT_OK, InfotypeServices/DCM_E_PENDING]
        arg OpStatus: type=Dcm_OpStatusType, direction=IN
        arg DataValueBuffer: type=Dcm_InfoTypeServicesArrayType, direction=OUT
        arg DataValueBufferSize: type=uint8, direction=INOUT  # When the function is called this parameter contains the maximum number of data bytes that can be written to the buffer. The function returns the actual number of written data bytes in DataValueBuffer
      error E_OK: error-code=0  # Operation successful
      error E_NOT_OK: error-code=1  # Operation failed
      error DCM_E_PENDING: error-code=10  # Request is not yet finished. Further call(s) required to finish.
    RequestControlServices
      operation RequestControl: possible-error=[RequestControlServices/E_OK, RequestControlServices/E_NOT_OK]
        arg OutBuffer: type=Dcm_RequestControlServicesOutArrayType, direction=OUT
        arg InBuffer: type=Dcm_RequestControlServicesInArrayType, direction=IN
      error E_OK: error-code=0  # Operation successful
      error E_NOT_OK: error-code=1  # Operation failed
    RequestFileTransfer: variation-point={short-label=RequestFileTransfer, blueprint-condition=p=l-1=({ecuc(Dcm/DcmConfigSet/DcmDsp/DcmDspRequestFileTransfer/DcmRequestFileTransferUsePort)} == TRUE)}
      7 x operation:
        ProcessRequestAddFile: possible-error=[RequestFileTransfer/E_OK, RequestFileTransfer/E_NOT_OK, RequestFileTransfer/DCM_E_PENDING, RequestFileTransfer/DCM_E_FORCE_RCRRP]  # Callout function. DCM shall call this function to start a RequestFileTransfer process with modeOfOperation equal to 0x01 (AddFile).
          8 x arg:
            OpStatus: type=Dcm_OpStatusType, direction=IN  # DCM_INITIAL: All In-parameters are valid. DCM_PENDING: All In-parameters are set to 0x00. DCM_CANCEL: All In-parameters are set to 0x00. DCM_FORCE_RCRRP_OK: All In-parameters are set to 0x00.
            filePathAndNameLength: type=uint16, direction=IN  # Defines the length in bytes for the parameter filePathAndName.
            filePathAndName: type=Dcm_FileAndDirNameType, direction=IN  # Defines the file system location of the server where the file which shall be added, deleted, replaced or read from depending on the parameter modeOfOperation parameter. In addition this parameter includes the file name of the file which shall be added, deleted, replaced or read as part of the file path.
            dataFormatIdentifier: type=uint8, direction=IN  # This data-parameter is a one byte value with each nibble encoded separately. The high nibble specifies the "compressionMethod", and the low nibble specifies the "encryptingMethod". The value 0x00 specifies that neither compressionMethod nor encryptingMethod is used. Values other than 0x00 are vehicle manufacturer specific.
            fileSizeUncompressed: type=uint64, direction=IN  # Defines the size of the uncompressed file to be download in bytes.
            fileSizeCompressed: type=uint64, direction=IN  # Defines the size of the compressed file to be downloaded in bytes.
            maxNumberOfBlockLength: type=uint64, direction=OUT  # Max number of bytes to be included in each TransferData request excluding the SID and the blockSequenceCounter.
            ErrorCode: type=Dcm_NegativeResponseCodeType, direction=OUT  # If the operation Dcm_ProcessRequestAddFile returns value E_NOT_OK, the DCM module shall send a negative response with NRC code equal to the parameter ErrorCode parameter value.
        ProcessRequestDeleteFile: possible-error=[RequestFileTransfer/E_OK, RequestFileTransfer/E_NOT_OK, RequestFileTransfer/DCM_E_PENDING, RequestFileTransfer/DCM_E_FORCE_RCRRP]  # Callout function. DCM shall call this function to start a RequestFileTransfer process with modeOfOperation equal to 0x02 (DeleteFile).
          4 x arg:
            OpStatus: type=Dcm_OpStatusType, direction=IN  # DCM_INITIAL: All In-parameters are valid. DCM_PENDING: All In-parameters are set to 0x00. DCM_CANCEL: All In-parameters are set to 0x00. DCM_FORCE_RCRRP_OK: All In-parameters are set to 0x00.
            filePathAndNameLength: type=uint16, direction=IN  # Defines the length in bytes for the parameter filePathAndName.
            filePathAndName: type=Dcm_FileAndDirNameType, direction=IN  # Defines the file system location of the server where the file which shall be added, deleted, replaced or read from depending on the parameter modeOfOperation parameter. In addition this parameter includes the file name of the file which shall be added, deleted, replaced or read as part of the file path.
            ErrorCode: type=Dcm_NegativeResponseCodeType, direction=OUT  # If the operation Dcm_ProcessRequestDeleteFile returns value E_NOT_OK, the DCM module shall send a negative response with NRC code equal to the parameter ErrorCode parameter value.
        ProcessRequestReadDir: possible-error=[RequestFileTransfer/E_OK, RequestFileTransfer/E_NOT_OK, RequestFileTransfer/DCM_E_PENDING, RequestFileTransfer/DCM_E_FORCE_RCRRP]  # Callout function. DCM shall call this function to start a RequestFileTransfer process with modeOfOperation equal to 0x05 (ReadDir).
          6 x arg:
            OpStatus: type=Dcm_OpStatusType, direction=IN  # DCM_INITIAL: All In-parameters are valid. DCM_PENDING: All In-parameters are set to 0x00. DCM_CANCEL: All In-parameters are set to 0x00. DCM_FORCE_RCRRP_OK: All In-parameters are set to 0x00.
            filePathAndNameLength: type=uint16, direction=IN  # Defines the length in bytes for the parameter filePathAndName.
            filePathAndName: type=Dcm_FileAndDirNameType, direction=IN  # Defines the file system location of the server where the file which shall be added, deleted, replaced or read from depending on the parameter modeOfOperation parameter. In addition this parameter includes the file name of the file which shall be added, deleted, replaced or read as part of the file path.
            dirInfoLength: type=uint64, direction=OUT  # Defines the size of directory information to be uploaded in bytes.
            maxNumberOfBlockLength: type=uint64, direction=OUT  # Max number of bytes to be included in each TransferData request excluding the SID and the blockSequenceCounter.
            ErrorCode: type=Dcm_NegativeResponseCodeType, direction=OUT  # If the operation Dcm_ProcessRequestReadDir returns value E_NOT_OK, the DCM module shall send a negative response with NRC code equal to the parameter ErrorCode parameter value.
        ProcessRequestReadFile: possible-error=[RequestFileTransfer/E_OK, RequestFileTransfer/E_NOT_OK, RequestFileTransfer/DCM_E_PENDING, RequestFileTransfer/DCM_E_FORCE_RCRRP]  # Callout function. DCM shall call this function to start a RequestFileTransfer process with modeOfOperation equal to 0x04 (ReadFile).
          8 x arg:
            OpStatus: type=Dcm_OpStatusType, direction=IN  # DCM_INITIAL: All In-parameters are valid. DCM_PENDING: All In-parameters are set to 0x00. DCM_CANCEL: All In-parameters are set to 0x00. DCM_FORCE_RCRRP_OK: All In-parameters are set to 0x00.
            filePathAndNameLength: type=uint16, direction=IN  # Defines the length in bytes for the parameter filePathAndName.
            filePathAndName: type=Dcm_FileAndDirNameType, direction=IN  # Defines the file system location of the server where the file which shall be added, deleted, replaced or read from depending on the parameter modeOfOperation parameter. In addition this parameter includes the file name of the file which shall be added, deleted, replaced or read as part of the file path.
            dataFormatIdentifier: type=uint8, direction=IN  # This data-parameter is a one byte value with each nibble encoded separately. The high nibble specifies the "compressionMethod", and the low nibble specifies the "encryptingMethod". The value 0x00 specifies that neither compressionMethod nor encryptingMethod is used. Values other than 0x00 are vehicle manufacturer specific.
            fileSizeUncompressed: type=uint64, direction=OUT  # Defines the size of the uncompressed file to be uploaded in bytes.
            fileSizeCompressed: type=uint64, direction=OUT  # Defines the size of the compressed file to be uploaded in bytes.
            maxNumberOfBlockLength: type=uint64, direction=OUT  # Max number of bytes to be included in each TransferData response excluding the SID and the blockSequenceCounter.
            ErrorCode: type=Dcm_NegativeResponseCodeType, direction=OUT  # If the operation Dcm_ProcessRequestReadFile returns value E_NOT_OK, the DCM module shall send a negative response with NRC code equal to the parameter ErrorCode parameter value.
        ProcessRequestReplaceFile: possible-error=[RequestFileTransfer/E_OK, RequestFileTransfer/E_NOT_OK, RequestFileTransfer/DCM_E_PENDING, RequestFileTransfer/DCM_E_FORCE_RCRRP]  # Callout function. DCM shall call this function to start a RequestFileTransfer process with modeOfOperation equal to 0x03 (ReplaceFile).
          8 x arg:
            OpStatus: type=Dcm_OpStatusType, direction=IN  # DCM_INITIAL: All In-parameters are valid. DCM_PENDING: All In-parameters are set to 0x00. DCM_CANCEL: All In-parameters are set to 0x00. DCM_FORCE_RCRRP_OK: All In-parameters are set to 0x00.
            filePathAndNameLength: type=uint16, direction=IN  # Defines the length in bytes for the parameter filePathAndName.
            filePathAndName: type=Dcm_FileAndDirNameType, direction=IN  # Defines the file system location of the server where the file which shall be added, deleted, replaced or read from depending on the parameter modeOfOperation parameter. In addition this parameter includes the file name of the file which shall be added, deleted, replaced or read as part of the file path.
            dataFormatIdentifier: type=uint8, direction=IN  # This data-parameter is a one byte value with each nibble encoded separately. The high nibble specifies the "compressionMethod", and the low nibble specifies the "encryptingMethod". The value 0x00 specifies that neither compressionMethod nor encryptingMethod is used. Values other than 0x00 are vehicle manufacturer specific.
            fileSizeUncompressed: type=uint64, direction=IN  # Defines the size of the uncompressed file to be download in bytes.
            fileSizeCompressed: type=uint64, direction=IN  # Defines the size of the compressed file to be downloaded in bytes.
            maxNumberOfBlockLength: type=uint64, direction=OUT  # Max number of bytes to be included in each TransferData request excluding the SID and the blockSequenceCounter.
            ErrorCode: type=Dcm_NegativeResponseCodeType, direction=OUT  # If the operation Dcm_ProcessRequestReplaceFile returns value E_NOT_OK, the DCM module shall send a negative response with NRC code equal to the parameter ErrorCode parameter value.
        ReadFileOrDir: possible-error=[RequestFileTransfer/E_OK, RequestFileTransfer/E_NOT_OK, RequestFileTransfer/DCM_E_PENDING, RequestFileTransfer/DCM_E_FORCE_RCRRP]  # Callout function. DCM shall call this function when data shall be sent as a response to UDS service TransferData if there's an ongoing RequestFileTransfer process started with 0x04 (ReadFile) or 0x05 (ReadDir).
          4 x arg:
            OpStatus: type=Dcm_OpStatusType, direction=IN  # DCM_INITIAL: All In-parameters are valid. DCM_PENDING: All In-parameters are set to 0x00. DCM_CANCEL: All In-parameters are set to 0x00. DCM_FORCE_RCRRP_OK: All In-parameters are set to 0x00.
            DataLength: type=uint64, direction=INOUT  # As in, the parameter defines the maximum block length to be used, i.e. the value of maxNumberOfBlockLength sent to the client in the response of RequestFileTransfer. As out, the parameter defines the actual length in bytes for the parameter Data. The value shall not exceed, but might be less, the value provided as in parameter.
            Data: type=Dcm_ResponseDataArrayType, direction=IN  # Pointer to the data to be written.
            ErrorCode: type=Dcm_NegativeResponseCodeType, direction=OUT  # If the operation Dcm_ReadFileOrDir returns value E_NOT_OK, the DCM module shall send a negative response with NRC code equal to the parameter ErrorCode parameter value.
        WriteFile  # Callout function. DCM shall call this function when data is received using UDS service TransferData if there's an ongoing RequestFileTransfer process started with 0x01 (AddFile) or 0x03 (ReplaceFile).
          4 x arg:
            OpStatus: type=Dcm_OpStatusType, direction=IN  # DCM_INITIAL: All In-parameters are valid. DCM_PENDING: All In-parameters are set to 0x00. DCM_CANCEL: All In-parameters are set to 0x00. DCM_FORCE_RCRRP_OK: All In-parameters are set to 0x00.
            DataLength: type=uint64, direction=IN  # Defines the length in bytes for the parameter Data. The value will not exceed, but might be less, compared to the value of maxNumberOfBlockLength return in Dcm_ProcessRequestFileTransfer.
            Data: type=Dcm_RequestDataArrayType, direction=IN  # Pointer to the data to be written.
            ErrorCode: type=Dcm_NegativeResponseCodeType, direction=OUT  # If the operation Dcm_WriteFile returns value E_NOT_OK, the DCM module shall send a negative response with NRC code equal to the parameter ErrorCode parameter value.
      4 x error:
        E_OK: error-code=0  # Operation successful
        E_NOT_OK: error-code=1  # Operation failed
        DCM_E_PENDING: error-code=10  # Request is not yet finished. Further call(s) required to finish.
        DCM_E_FORCE_RCRRP: error-code=12  # application request the transmission of a response Response Pending (NRC 0x78)
    ServiceRequestNotification: variation-point={short-label=ServiceRequestNotification, blueprint-condition=p=l-1=({ecuc(Dcm/DcmConfigSet/DcmDsd/DcmDsdServiceRequestManufacturerNotification)} != NULL)||({ecuc(Dcm/DcmConfigSet/DcmDsd/DcmDsdServiceRequestSupplierNotification)} != NULL)}
      operation Confirmation: possible-error=[ServiceRequestNotification/E_OK, ServiceRequestNotification/E_NOT_OK]
        6 x arg, all with direction=IN:
          SID: type=uint8  # Value of service identifier
          ReqType: type=uint8  # Addressing type of the request(0=physical request, 1=functional request)
          ConnectionId: type=uint16  # Unique connection identifier
          ConfirmationStatus: type=Dcm_ConfirmationStatusType  # Confirmation of a successful transmission or a transmission error of a diagnostic service.
          ProtocolType: type=Dcm_ProtocolType
          TesterSourceAddress: type=uint16
      operation Indication: possible-error=[ServiceRequestNotification/E_OK, ServiceRequestNotification/E_NOT_OK, E_REQUEST_NOT_ACCEPTED]
        8 x arg:
          SID: type=uint8, direction=IN  # Value of service identifier
          RequestData: type=Dcm_RequestDataArrayType, direction=IN  # This parameter contains the complete request data (diagnostic buffer), except the service ID
          DataSize: type=uint16, direction=IN  # This parameter defines how many bytes in the RequestData parameter are valid
          ReqType: type=uint8, direction=IN  # Addressing type of the request(0=physical request, 1=functional request
          ConnectionId: type=uint16, direction=IN  # Unique connection identifier
          ErrorCode: type=Dcm_NegativeResponseCodeType, direction=OUT
          ProtocolType: type=Dcm_ProtocolType, direction=IN
          TesterSourceAddress: type=uint16, direction=IN
      error E_OK: error-code=0  # Operation successful
      error E_NOT_OK: error-code=1  # Operation failed
      error E_REQUEST_NOT_ACCEPTED: error-code=8  # no response will be sent
    RoutineServices: variation-point={short-label=RoutineServices, blueprint-condition=p=l-1={ecuc(Dcm/DcmConfigSet/DcmDsp/DcmDspRoutine.DcmDspRoutineUsePort)} == TRUE}
      15 x operation:
        RequestResults: possible-error=[RoutineServices/E_OK, RoutineServices/E_NOT_OK, RoutineServices/DCM_E_PENDING, RoutineServices/DCM_E_FORCE_RCRRP], variation-point=blueprint-condition=p=l-1=({ecuc(Dcm/DcmConfigSet/DcmDsp/DcmDspRoutine/DcmDspRequestRoutineResults/DcmDspRequestRoutineResultsOut/DcmDspRequestRoutineResultsOutSignal.DcmDspRoutineSignalType)} != VARIABLE_LENGTH) &&({ecuc(Dcm/DcmConfigSet/DcmDsp/DcmDspRoutine/DcmDspRequestRoutineResults/DcmDspRequestRoutineResultsIn/DcmDspRequestRoutineResultsInSignal.DcmDspRoutineSignalType)} != VARIABLE_LENGTH)
          4 x arg:
            DataInX: type=Dcm_RequestDataInType, direction=IN
            OpStatus: type=Dcm_OpStatusType, direction=IN
            DataOutX: type=Dcm_RequestDataOutType, direction=OUT
            ErrorCode: type=Dcm_NegativeResponseCodeType, direction=OUT
        RequestResults: variation-point=blueprint-condition=p=l-1=({ecuc(Dcm/DcmConfigSet/DcmDsp/DcmDspRoutine/DcmDspRequestRoutineResults/DcmDspRequestRoutineResultsOut/DcmDspRequestRoutineResultsOutSignal.DcmDspRoutineSignalType)} == VARIABLE_LENGTH) &&({ecuc(Dcm/DcmConfigSet/DcmDsp/DcmDspRoutine/DcmDspRequestRoutineResults/DcmDspRequestRoutineResultsIn/DcmDspRequestRoutineResultsInSignal.DcmDspRoutineSignalType)} != VARIABLE_LENGTH)
          6 x arg:
            DataInX: type=Dcm_RequestDataInType, direction=IN
            OpStatus: type=Dcm_OpStatusType, direction=IN
            DataOutX: type=Dcm_RequestDataOutType, direction=OUT, variation-point=blueprint-condition=p=l-1={ecuc(Dcm/DcmConfigSet/DcmDsp/DcmDspRoutine/DcmDspRequestRoutineResults/DcmDspRequestRoutineResultsOut/DcmDspRequestRoutineResultsOutSignal.DcmDspRoutineSignalType)} != VARIABLE_LENGTH
            DataOutN: type=Dcm_RequestFlexibleOutArrayDataType, direction=OUT, variation-point=blueprint-condition=p=l-1={ecuc(Dcm/DcmConfigSet/DcmDsp/DcmDspRoutine/DcmDspRequestRoutineResults/DcmDspRequestRoutineResultsOut/DcmDspRequestRoutineResultsOutSignal.DcmDspRoutineSignalType)} == VARIABLE_LENGTH
            currentDataLength: type=uint16, direction=OUT
            ErrorCode: type=Dcm_NegativeResponseCodeType, direction=OUT
        RequestResults: variation-point=blueprint-condition=p=l-1=({ecuc(Dcm/DcmConfigSet/DcmDsp/DcmDspRoutine/DcmDspRequestRoutineResults/DcmDspRequestRoutineResultsOut/DcmDspRequestRoutineResultsOutSignal.DcmDspRoutineSignalType)} != VARIABLE_LENGTH) &&({ecuc(Dcm/DcmConfigSet/DcmDsp/DcmDspRoutine/DcmDspRequestRoutineResults/DcmDspRequestRoutineResultsIn/DcmDspRequestRoutineResultsInSignal.DcmDspRoutineSignalType)} == VARIABLE_LENGTH)
          5 x arg:
            DataInX: type=Dcm_RequestDataInType, direction=IN
            DataInN: type=Dcm_RequestFlexibleInArrayDataType, direction=IN
            OpStatus: type=Dcm_OpStatusType, direction=IN
            DataOutX: type=Dcm_RequestDataOutType, direction=OUT
            ErrorCode: type=Dcm_NegativeResponseCodeType, direction=OUT
        RequestResults: possible-error=[RoutineServices/E_OK, RoutineServices/E_NOT_OK, RoutineServices/DCM_E_PENDING, RoutineServices/DCM_E_FORCE_RCRRP], variation-point=blueprint-condition=p=l-1=({ecuc(Dcm/DcmConfigSet/DcmDsp/DcmDspRoutine/DcmDspRequestRoutineResults/DcmDspRequestRoutineResultsOut/DcmDspRequestRoutineResultsOutSignal.DcmDspRoutineSignalType)} == VARIABLE_LENGTH) &&({ecuc(Dcm/DcmConfigSet/DcmDsp/DcmDspRoutine/DcmDspRequestRoutineResults/DcmDspRequestRoutineResultsIn/DcmDspRequestRoutineResultsInSignal.DcmDspRoutineSignalType)} == VARIABLE_LENGTH)
          7 x arg:
            DataInX: type=Dcm_RequestDataInType, direction=IN
            DataInN: type=Dcm_StartFlexibleInArrayDataType, direction=IN
            OpStatus: type=Dcm_OpStatusType, direction=IN
            DataOutX: type=Dcm_RequestDataOutType, direction=OUT, variation-point=blueprint-condition=p=l-1={ecuc(Dcm/DcmConfigSet/DcmDsp/DcmDspRoutine/DcmDspRequestRoutineResults/DcmDspRequestRoutineResultsOut/DcmDspRequestRoutineResultsOutSignal.DcmDspRoutineSignalType)} != VARIABLE_LENGTH
            DataOutN: type=Dcm_RequestFlexibleOutArrayDataType, direction=OUT, variation-point=blueprint-condition=p=l-1={ecuc(Dcm/DcmConfigSet/DcmDsp/DcmDspRoutine/DcmDspRequestRoutineResults/DcmDspRequestRoutineResultsOut/DcmDspRequestRoutineResultsOutSignal.DcmDspRoutineSignalType)} == VARIABLE_LENGTH
            currentDataLength: type=uint16, direction=OUT
            ErrorCode: type=Dcm_NegativeResponseCodeType, direction=OUT
        RequestResultsConfirmation: possible-error=[RoutineServices/E_OK, RoutineServices/E_NOT_OK], variation-point=blueprint-condition=p=l-1=({ecuc(Dcm/DcmConfigSet/DcmDsp/DcmDspRoutine/DcmDspRequestRoutineResults/DcmDspRequestRoutineResultsConfirmationEnabled)}==TRUE)  # This operation indicates the transmission of a response to a RequestResultsRoutine request
          arg ConfirmationStatus: type=Dcm_ConfirmationStatusType, direction=IN  # Confirmation status of a RequestResultsRoutinerequest
        Start: possible-error=[RoutineServices/E_OK, RoutineServices/E_NOT_OK, RoutineServices/DCM_E_PENDING, RoutineServices/DCM_E_FORCE_RCRRP], variation-point=blueprint-condition=[l-1=({ecuc(Dcm/DcmConfigSet/DcmDsp/DcmDspRoutine/DcmDspStartRoutine/DcmDspStartRoutineIn/DcmDspStartRoutineInSignal.DcmDspRoutineSignalType)} != VARIABLE_LENGTH) &&, l-1=({ecuc(Dcm/DcmConfigSet/DcmDsp/DcmDspRoutine/DcmDspStartRoutine/DcmDspStartRoutineOut/DcmDspStartRoutineOutSignal.DcmDspRoutineSignalType)} != VARIABLE_LENGTH)]
          4 x arg:
            DataInX: type=Dcm_StartDataInType, direction=IN
            OpStatus: type=Dcm_OpStatusType, direction=IN
            DataOutX: type=Dcm_StartDataOutType, direction=OUT
            ErrorCode: type=Dcm_NegativeResponseCodeType, direction=OUT
        Start: possible-error=[RoutineServices/E_OK, RoutineServices/E_NOT_OK, RoutineServices/DCM_E_PENDING, RoutineServices/DCM_E_FORCE_RCRRP], variation-point=blueprint-condition=[l-1=({ecuc(Dcm/DcmConfigSet/DcmDsp/DcmDspRoutine/DcmDspStartRoutine/DcmDspStartRoutineIn/DcmDspStartRoutineInSignal.DcmDspRoutineSignalType)} != VARIABLE_LENGTH) &&, l-1=({ecuc(Dcm/DcmConfigSet/DcmDsp/DcmDspRoutine/DcmDspStartRoutine/DcmDspStartRoutineOut/DcmDspStartRoutineOutSignal.DcmDspRoutineSignalType)} == VARIABLE_LENGTH)]
          6 x arg:
            DataInX: type=Dcm_StartDataInType, direction=IN
            OpStatus: type=Dcm_OpStatusType, direction=IN
            DataOutX: type=Dcm_StartDataOutType, direction=OUT
            DataOutN: type=Dcm_StartFlexibleOutArrayDataType, direction=OUT
            currentDataLength: type=uint16, direction=OUT
            ErrorCode: type=Dcm_NegativeResponseCodeType, direction=OUT
        Start: possible-error=[RoutineServices/E_OK, RoutineServices/E_NOT_OK, RoutineServices/DCM_E_PENDING, RoutineServices/DCM_E_FORCE_RCRRP], variation-point=blueprint-condition=[l-1=({ecuc(Dcm/DcmConfigSet/DcmDsp/DcmDspRoutine/DcmDspStartRoutine/DcmDspStartRoutineIn/DcmDspStartRoutineInSignal.DcmDspRoutineSignalType)} == VARIABLE_LENGTH) &&, l-1=({ecuc(Dcm/DcmConfigSet/DcmDsp/DcmDspRoutine/DcmDspStartRoutine/DcmDspStartRoutineOut/DcmDspStartRoutineOutSignal.DcmDspRoutineSignalType)} != VARIABLE_LENGTH)]
          6 x arg:
            DataInX: type=Dcm_StartDataInType, direction=IN
            DataInN: type=Dcm_StartFlexibleInArrayDataType, direction=IN
            OpStatus: type=Dcm_OpStatusType, direction=IN
            DataOutX: type=Dcm_StartDataOutType, direction=OUT
            currentDataLength: type=uint16, direction=IN
            ErrorCode: type=Dcm_NegativeResponseCodeType, direction=OUT
        Start: possible-error=[RoutineServices/E_OK, RoutineServices/E_NOT_OK, RoutineServices/DCM_E_PENDING, RoutineServices/DCM_E_FORCE_RCRRP], variation-point=blueprint-condition=[l-1=({ecuc(Dcm/DcmConfigSet/DcmDsp/DcmDspRoutine/DcmDspStartRoutine/DcmDspStartRoutineIn/DcmDspStartRoutineInSignal.DcmDspRoutineSignalType)} == VARIABLE_LENGTH) &&, l-1=({ecuc(Dcm/DcmConfigSet/DcmDsp/DcmDspRoutine/DcmDspStartRoutine/DcmDspStartRoutineOut/DcmDspStartRoutineOutSignal.DcmDspRoutineSignalType)} == VARIABLE_LENGTH)]
          7 x arg:
            DataInX: type=Dcm_StartDataInType, direction=IN, variation-point=blueprint-condition=p=l-1={ecuc(Dcm/DcmConfigSet/DcmDsp/DcmDspRoutine/DcmDspStartRoutine/DcmDspStartRoutineIn/DcmDspStartRoutineInSignal.DcmDspRoutineSignalType)} != VARIABLE_LENGTH
            DataInN: type=Dcm_StartFlexibleInArrayDataType, direction=IN, variation-point=blueprint-condition=p=l-1={ecuc(Dcm/DcmConfigSet/DcmDsp/DcmDspRoutine/DcmDspStartRoutine/DcmDspStartRoutineIn/DcmDspStartRoutineInSignal.DcmDspRoutineSignalType)} == VARIABLE_LENGTH
            OpStatus: type=Dcm_OpStatusType, direction=IN
            DataOutX: type=Dcm_StartDataOutType, direction=OUT, variation-point=blueprint-condition=p=l-1={ecuc(Dcm/DcmConfigSet/DcmDsp/DcmDspRoutine/DcmDspStartRoutine/DcmDspStartRoutineOut/DcmDspStartRoutineOutSignal.DcmDspRoutineSignalType)} != VARIABLE_LENGTH
            DataOutN: type=Dcm_StartFlexibleOutArrayDataType, direction=OUT, variation-point=blueprint-condition=p=l-1={ecuc(Dcm/DcmConfigSet/DcmDsp/DcmDspRoutine/DcmDspStartRoutine/DcmDspStartRoutineOut/DcmDspStartRoutineOutSignal.DcmDspRoutineSignalType)} == VARIABLE_LENGTH
            currentDataLength: type=uint16, direction=INOUT
            ErrorCode: type=Dcm_NegativeResponseCodeType, direction=OUT
        StartConfirmation: possible-error=[RoutineServices/E_OK, RoutineServices/E_NOT_OK], variation-point=blueprint-condition=p=l-1={ecuc(Dcm/DcmConfigSet/DcmDsp/DcmDspRoutine/DcmDspStartRoutine/DcmDspStartRoutineConfirmationEnabled)}==TRUE  # This operation indicates the transmission of a response to a StartRoutine request
          arg ConfirmationStatus: type=Dcm_ConfirmationStatusType, direction=IN  # Confirmation status of a StartRoutine request
        Stop: possible-error=[RoutineServices/E_OK, RoutineServices/E_NOT_OK, RoutineServices/DCM_E_PENDING, RoutineServices/DCM_E_FORCE_RCRRP], variation-point=blueprint-condition=[l-1=({ecuc(Dcm/DcmConfigSet/DcmDsp/DcmDspRoutine/DcmDspStopRoutine/DcmDspStopRoutineIn/DcmDspStopRoutineInSignal.DcmDspRoutineSignalType)} != VARIABLE_LENGTH) &&, l-1=({ecuc(Dcm/DcmConfigSet/DcmDsp/DcmDspRoutine/DcmDspStopRoutine/DcmDspStopRoutineOut/DcmDspStopRoutineOutSignal.DcmDspRoutineSignalType)} != VARIABLE_LENGTH)]
          4 x arg:
            DataInX: type=Dcm_StopDataInType, direction=IN
            OpStatus: type=Dcm_OpStatusType, direction=IN
            DataOutX: type=Dcm_StopDataOutType, direction=OUT
            ErrorCode: type=Dcm_NegativeResponseCodeType, direction=OUT
        Stop: possible-error=[RoutineServices/E_OK, RoutineServices/E_NOT_OK, RoutineServices/DCM_E_PENDING, RoutineServices/DCM_E_FORCE_RCRRP], variation-point=blueprint-condition=[l-1=({ecuc(Dcm/DcmConfigSet/DcmDsp/DcmDspRoutine/DcmDspStopRoutine/DcmDspStopRoutineIn/DcmDspStopRoutineInSignal.DcmDspRoutineSignalType)} != VARIABLE_LENGTH) &&, l-1=({ecuc(Dcm/DcmConfigSet/DcmDsp/DcmDspRoutine/DcmDspStopRoutine/DcmDspStopRoutineOut/DcmDspStopRoutineOutSignal.DcmDspRoutineSignalType)} == VARIABLE_LENGTH)]
          6 x arg:
            DataInX: type=Dcm_StopDataInType, direction=IN
            OpStatus: type=Dcm_OpStatusType, direction=IN
            DataOutX: type=Dcm_StopDataOutType, direction=OUT
            DataOutN: type=Dcm_StopFlexibleOutArrayDataType, direction=OUT
            currentDataLength: type=uint16, direction=OUT
            ErrorCode: type=Dcm_NegativeResponseCodeType, direction=OUT
        Stop: possible-error=[RoutineServices/E_OK, RoutineServices/E_NOT_OK, RoutineServices/DCM_E_PENDING, RoutineServices/DCM_E_FORCE_RCRRP], variation-point=blueprint-condition=[l-1=({ecuc(Dcm/DcmConfigSet/DcmDsp/DcmDspRoutine/DcmDspStopRoutine/DcmDspStopRoutineIn/DcmDspStopRoutineInSignal.DcmDspRoutineSignalType)} == VARIABLE_LENGTH) &&, l-1=({ecuc(Dcm/DcmConfigSet/DcmDsp/DcmDspRoutine/DcmDspStopRoutine/DcmDspStopRoutineOut/DcmDspStopRoutineOutSignal.DcmDspRoutineSignalType)} != VARIABLE_LENGTH)]
          6 x arg:
            DataInX: type=Dcm_StopDataInType, direction=IN
            DataInN: type=Dcm_StopFlexibleInArrayDataType, direction=IN
            OpStatus: type=Dcm_OpStatusType, direction=IN
            DataOutX: type=Dcm_StopDataOutType, direction=OUT
            currentDataLength: type=uint16, direction=IN
            ErrorCode: type=Dcm_NegativeResponseCodeType, direction=OUT
        Stop: possible-error=[RoutineServices/E_OK, RoutineServices/E_NOT_OK, RoutineServices/DCM_E_PENDING, RoutineServices/DCM_E_FORCE_RCRRP], variation-point=blueprint-condition=[l-1=({ecuc(Dcm/DcmConfigSet/DcmDsp/DcmDspRoutine/DcmDspStopRoutine/DcmDspStopRoutineIn/DcmDspStopRoutineInSignal.DcmDspRoutineSignalType)} == VARIABLE_LENGTH) &&, l-1=({ecuc(Dcm/DcmConfigSet/DcmDsp/DcmDspRoutine/DcmDspStopRoutine/DcmDspStopRoutineOut/DcmDspStopRoutineOutSignal.DcmDspRoutineSignalType)} == VARIABLE_LENGTH)]
          7 x arg:
            DataInX: type=Dcm_StopDataInType, direction=IN, variation-point=blueprint-condition=p=l-1={ecuc(Dcm/DcmConfigSet/DcmDsp/DcmDspRoutine/DcmDspStopRoutine/DcmDspStopRoutineIn/DcmDspStopRoutineInSignal.DcmDspRoutineSignalType)} != VARIABLE_LENGTH
            DataInN: type=Dcm_StopFlexibleInArrayDataType, direction=IN, variation-point=blueprint-condition=p=l-1={ecuc(Dcm/DcmConfigSet/DcmDsp/DcmDspRoutine/DcmDspStopRoutine/DcmDspStopRoutineIn/DcmDspStopRoutineInSignal.DcmDspRoutineSignalType)} == VARIABLE_LENGTH
            OpStatus: type=Dcm_OpStatusType, direction=IN
            DataOutX: type=Dcm_StopDataOutType, direction=OUT, variation-point=blueprint-condition=p=l-1={ecuc(Dcm/DcmConfigSet/DcmDsp/DcmDspRoutine/DcmDspStopRoutine/DcmDspStopRoutineOut/DcmDspStopRoutineOutSignal.DcmDspRoutineSignalType)} != VARIABLE_LENGTH
            DataOutN: type=Dcm_StopFlexibleOutArrayDataType, direction=OUT, variation-point=blueprint-condition=p=l-1={ecuc(Dcm/DcmConfigSet/DcmDsp/DcmDspRoutine/DcmDspStopRoutine/DcmDspStopRoutineOut/DcmDspStopRoutineOutSignal.DcmDspRoutineSignalType)} == VARIABLE_LENGTH
            currentDataLength: type=uint16, direction=INOUT
            ErrorCode: type=Dcm_NegativeResponseCodeType, direction=OUT
        StopConfirmation: possible-error=[RoutineServices/E_OK, RoutineServices/E_NOT_OK], variation-point=blueprint-condition=p=l-1=({ecuc(Dcm/DcmConfigSet/DcmDsp/DcmDspRoutine/DcmDspStopRoutine/DcmDspStopRoutineConfirmationEnabled)}==TRUE)  # This operation indicates the transmission of a response to a StopRoutine request
          arg ConfirmationStatus: type=Dcm_ConfirmationStatusType, direction=IN  # Confirmation status of a StopRoutine request
      4 x error:
        E_OK: error-code=0  # Operation successful
        E_NOT_OK: error-code=1  # Operation failed
        DCM_E_PENDING: error-code=10  # Request is not yet finished. Further call(s) required to finish.
        DCM_E_FORCE_RCRRP: error-code=12  # application request the transmission of a response Response Pending (NRC 0x78)
    SecurityAccess: variation-point={short-label=SecurityAccess, blueprint-condition=p=l-1={ecuc(Dcm/DcmConfigSet/DcmDsp/DcmDspSecurity/DcmDspSecurityRow.DcmDspSecurityUsePort)} == USE_ASYNCH_CLIENT_SERVER}
      5 x operation:
        CompareKey: possible-error=[SecurityAccess/E_OK, SecurityAccess/E_NOT_OK, SecurityAccess/DCM_E_PENDING, DCM_E_COMPARE_KEY_FAILED]
          arg Key: type=Dcm_KeyArrayType, direction=IN  # Key, which needs to be compared
          arg OpStatus: type=Dcm_OpStatusType, direction=IN
          arg ErrorCode: type=Dcm_NegativeResponseCodeType, direction=OUT  # return Error Code
        GetSecurityAttemptCounter: possible-error=[SecurityAccess/E_OK, SecurityAccess/E_NOT_OK, SecurityAccess/DCM_E_PENDING], variation-point=blueprint-condition=p=l-1={ecuc(Dcm/DcmConfigSet/DcmDsp/DcmDspSecurity/DcmDspSecurityRow.DcmDspSecurityAttemptCounterEnabled)} == TRUE  # Restore the attempt counter from the application
          arg OpStatus: type=Dcm_OpStatusType, direction=IN
          arg AttemptCounter: type=uint8, direction=OUT
        GetSeed: possible-error=[SecurityAccess/E_OK, SecurityAccess/E_NOT_OK, SecurityAccess/DCM_E_PENDING], variation-point=blueprint-condition=p=l-1=({ecuc(Dcm/DcmConfigSet/DcmDsp/DcmDspSecurity/DcmDspSecurityRow.DcmDspSecurityADRSize)} == NULL)
          arg OpStatus: type=Dcm_OpStatusType, direction=IN
          arg Seed: type=Dcm_SeedArrayType, direction=OUT  # Pointer for provided seed
          arg ErrorCode: type=Dcm_NegativeResponseCodeType, direction=OUT
        GetSeed: possible-error=[SecurityAccess/E_OK, SecurityAccess/E_NOT_OK, SecurityAccess/DCM_E_PENDING], variation-point=blueprint-condition=p=l-1=({ecuc(Dcm/DcmConfigSet/DcmDsp/DcmDspSecurity/DcmDspSecurityRow.DcmDspSecurityADRSize)} != NULL)
          4 x arg:
            SecurityAccessDataRecord: type=Dcm_SecurityAccessDataRecordType, direction=IN
            OpStatus: type=Dcm_OpStatusType, direction=IN
            Seed: type=Dcm_SeedArrayType, direction=OUT  # Pointer for provided seed
            ErrorCode: type=Dcm_NegativeResponseCodeType, direction=OUT
        SetSecurityAttemptCounter: possible-error=[SecurityAccess/E_OK, SecurityAccess/E_NOT_OK, SecurityAccess/DCM_E_PENDING], variation-point=blueprint-condition=p=l-1={ecuc(Dcm/DcmConfigSet/DcmDsp/DcmDspSecurity/DcmDspSecurityRow.DcmDspSecurityAttemptCounterEnabled)} == TRUE  # Store the attempt counter in the application
          arg OpStatus: type=Dcm_OpStatusType, direction=IN
          arg AttemptCounter: type=uint8, direction=IN
      4 x error:
        E_OK: error-code=0  # Operation successful
        E_NOT_OK: error-code=1  # Operation failed
        DCM_E_PENDING: error-code=10  # Request is not yet finished. Further call(s) required to finish.
        DCM_E_COMPARE_KEY_FAILED: error-code=11  # Key did not match.
    UploadDownloadServices: variation-point={short-label=UploadDownloadServices, blueprint-condition=p=l-1={ecuc(Dcm/DcmConfigSet/DcmDsp/DcmDspMemoryTransfer.DcmDspMemoryTransferUsePort)} == TRUE)}
      5 x operation:
        ProcessRequestDownload: possible-error=[UploadDownloadServices/E_OK, UploadDownloadServices/E_NOT_OK, UploadDownloadServices/DCM_E_PENDING]  # Callout function. DCM shall call this callout function to start a download process. This service is needed for the implementation of UDS service RequestDownload.
          7 x arg:
            OpStatus: type=Dcm_OpStatusType, direction=IN  # DCM_INITIAL DCM_PENDING DCM_CANCEL
            DataFormatIdentifier: type=uint8, direction=IN  # Bit 7 - 4: Compression Method - 0x0: not compressed - 0x1..F: vehicle-manufacturer-specific Bit 3 - 0: Encrypting method - 0x0: not encrypted - 0x1..F: vehicle-manufacturer-specific
            MemoryIdentifier: type=uint8, direction=IN  # Identifier of the Memory Block, if the parameter is not used it shall be set to 0.
            MemoryAddress: type=uint32, direction=IN  # Starting address of server memory to which data is to be written
            MemorySize: type=uint32, direction=IN  # Uncompressed memory size in bytes
            BlockLength: type=uint32, direction=INOUT  # Max. Number of bytes for one Dcm_WriteMemory
            ErrorCode: type=Dcm_NegativeResponseCodeType, direction=OUT  # If the operation Dcm_ProcessRequestDownload returns value E_NOT_OK, the DCM module shall send a negative response with NRC code equal to the parameter ErrorCode parameter value.
        ProcessRequestTransferExit: possible-error=[UploadDownloadServices/E_OK, UploadDownloadServices/E_NOT_OK, UploadDownloadServices/DCM_E_PENDING]  # Callout function. DCM shall call this callout function to terminate a download or upload process. This callout is needed for the implementation of UDS service RequestTransferExit.
          arg OpStatus: type=Dcm_OpStatusType, direction=IN  # DCM_INITIAL DCM_PENDING DCM_CANCEL
          arg ErrorCode: type=Dcm_NegativeResponseCodeType, direction=OUT  # see below
        ProcessRequestUpload: possible-error=[UploadDownloadServices/E_OK, UploadDownloadServices/E_NOT_OK, UploadDownloadServices/DCM_E_PENDING]  # Callout function. DCM shall call this callout function to start an upload process. This service is needed for the implementation of UDS service RequestUpload.
          7 x arg:
            OpStatus: type=Dcm_OpStatusType, direction=IN  # DCM_INITIAL DCM_PENDING DCM_CANCEL DCM_FORCE_RCRRP_OK
            DataFormatIdentifier: type=uint8, direction=IN  # Bit 7 - 4: Compression Method - 0x0: not compressed - 0x1..F: vehicle-manufacturer-specific Bit 3 - 0: Encrypting method - 0x0: not encrypted - 0x1..F: vehicle-manufacturer-specific
            MemoryIdentifier: type=uint8, direction=IN  # Identifier of the Memory Block, if the parameter is not used it shall be set to 0.
            MemoryAddress: type=uint32, direction=IN  # Starting address of server memory from which data are to be copied
            MemorySize: type=uint32, direction=IN  # Uncompressed memory size in bytes
            BlockLength: type=uint32, direction=INOUT  # Max. Number of bytes for one Dcm_ReadMemory
            ErrorCode: type=Dcm_NegativeResponseCodeType, direction=OUT  # If the operation Dcm_ProcessRequestUpload returns value E_NOT_OK, the DCM module shall send a negative response with NRC code equal to the parameter ErrorCode parameter value.
        ProcessTransferDataRead: possible-error=[UploadDownloadServices/E_OK, UploadDownloadServices/E_NOT_OK, UploadDownloadServices/DCM_E_PENDING, UploadDownloadServices/DCM_E_FORCE_RCRRP]  # The ProcessTransferDataRead callout is used to request memory data identified by the parameter memoryAddress and memorySize from the UDS request message. This service is needed for the implementation of UDS services: - ReadMemoryByAddress - RequestUpload - ReadDataByIdentifier (in case of Dynamical DID defined by memory address) - TransferData
          6 x arg:
            OpStatus: type=Dcm_OpStatusType, direction=IN  # DCM_INITIAL DCM_PENDING DCM_CANCEL DCM_FORCE_RCRRP_OK
            MemoryIdentifier: type=uint8, direction=IN  # Identifier of the Memory Block (e.g. used if memory section distinguishing is needed) Note: If it's not used this parameter shall be set to 0.
            MemoryAddress: type=uint32, direction=IN  # Starting address of server memory from which data is to be retrieved.
            MemorySize: type=uint32, direction=IN  # Number of bytes in the MemoryData
            MemoryData: type=Dcm_RequestDataArrayType, direction=OUT  # Data read (Points to the diagnostic buffer in DCM)
            ErrorCode: type=Dcm_NegativeResponseCodeType, direction=OUT  # If the operation Dcm_ReadMemory returns value DCM_READ_FAILED, the Dcm module shall send a negative response with NRC code equal to the parameter ErrorCode parameter value.
        ProcessTransferDataWrite: possible-error=[UploadDownloadServices/E_OK, UploadDownloadServices/E_NOT_OK, UploadDownloadServices/DCM_E_PENDING, UploadDownloadServices/DCM_E_FORCE_RCRRP]  # The ProcessTransferDataWrite callout is used to write memory data identified by the parameter memoryAddress and memorySize. This service is needed for the implementation of UDS services : - WriteMemoryByAddress - RequestDownload - TransferData
          6 x arg:
            OpStatus: type=Dcm_OpStatusType, direction=IN  # DCM_INITIAL DCM_PENDING DCM_CANCEL DCM_FORCE_RCRRP_OK
            MemoryIdentifier: type=uint8, direction=IN  # Identifier of the Memory Block (e.g. used by WriteDataByIdentifier service). Note: If it's not used this parameter shall be set to 0.
            MemoryAddress: type=uint32, direction=IN  # Starting address of server memory in which data is to be copied. Note: If it's not used (e.g. if the data is compressed) this parameter shall be set to 0.
            MemorySize: type=uint32, direction=IN  # Number of bytes in MemoryData
            MemoryData: type=Dcm_RequestDataArrayType, direction=IN  # Data to write (Points to the diagnostic buffer in DCM)
            ErrorCode: type=Dcm_NegativeResponseCodeType, direction=OUT  # If the operation Dcm_WriteMemory returns value DCM_WRITE_FAILED, the Dcm module shall send a negative response with NRC code equal to the parameter ErrorCode parameter value.
      4 x error:
        E_OK: error-code=0  # Operation successful
        E_NOT_OK: error-code=1  # Operation failed
        DCM_E_PENDING: error-code=10  # Request is not yet finished. Further call(s) required to finish.
        DCM_E_FORCE_RCRRP: error-code=12  # application request the transmission of a response Response Pending (NRC 0x78)
package /AUTOSAR/Dcm/SenderReceiverInterfaces_Blueprint
  5 x sender receiver interface:
    DataServices_DID: variation-point={short-label=DataServices_DID_NvD, blueprint-condition=p=l-1=( {ecuc(Dcm/DcmConfigSet/DcmDsp/DcmDspDid/DcmDspDidUsePort)} == USE_ATOMIC_NV_DATA_INTERFACE)}
      data data: implementation-data-type=Dcm_DID_Struct_DataType, variation-point=blueprint-condition=p=l-1=DID = ({ecuc(Dcm/DcmConfigSet/DcmDsp/DcmDspDid.SHORT-NAME)})
    DataServices_DID: variation-point={short-label=DataServices_DID_SR, blueprint-condition=p=l-1=(({ecuc(Dcm/DcmConfigSet/DcmDsp/DcmDspDid/DcmDspDidUsePort)} == (USE_ATOMIC_SENDER_RECEIVER_INTERFACE) ||({ecuc(Dcm/DcmConfigSet/DcmDsp/DcmDspDid/DcmDspDidUsePort)} == (USE_ATOMIC_SENDER_RECEIVER_INTERFACE_AS_SERVICE))}, is-service=true
      data data: implementation-data-type=Dcm_DID_Struct_DataType, variation-point=blueprint-condition=p=l-1=DID = {ecuc(Dcm/DcmConfigSet/DcmDsp/DcmDspDid.SHORT-NAME)}
    DataServices: variation-point={short-label=DataServicesSR, blueprint-condition=p=l-1=(({ecuc(Dcm/DcmConfigSet/DcmDsp/DcmDspDid/DcmDspDidUsePort)} == USE_DATA_ELEMENT_SPECIFIC_INTERFACES)&&({ecuc(Dcm/DcmConfigSet/DcmDsp/DcmDspData/DcmDspDataUsePort)} == (USE_DATA_SENDER_RECEIVER ||USE_DATA_SENDER_RECEIVER_AS_SERVICE))) ||({ecuc(Dcm/DcmConfigSet/DcmDsp/DcmDspPid/DcmDspPidData/DcmDspPidService01/DcmDspPidDataUsePort)} ==(USE_DATA_SENDER_RECEIVER ||USE_DATA_SENDER_RECEIVER_AS_SERVICE))}
      data data: implementation-data-type=Dcm_DataElementType, variation-point=blueprint-condition=p=l-1=Data = ({ecuc(Dcm/DcmConfigSet/DcmDsp/DcmDspData.SHORT-NAME)}) || ({ecuc(Dcm/DcmConfigSet/DcmDsp/DcmDspPid/DcmDspPidData.SHORT-NAME)})
    IOControlRequest: variation-point={short-label=IOControlRequest, blueprint-condition=p=l-1=(({ecuc(Dcm/DcmConfigSet/DcmDsp/DcmDspDid/DcmDspDidUsePort)} == (USE_ATOMIC_SENDER_RECEIVER_INTERFACE ) ||({ecuc(Dcm/DcmConfigSet/DcmDsp/DcmDspDid/DcmDspDidUsePort)} == (USE_ATOMIC_SENDER_RECEIVER_INTERFACE_AS_SERVICE )) &&({ecuc(Dcm/DcmConfigSet/DcmDsp/DcmDspDid/DcmDspDidInfoRef-> DcmDspDidInfo/DcmDspDidControl)} != NULL))}, is-service=true  # Attention: controlState is only valid in case of IOOperationRequest is set to shortTermAdjustment. The DCM provides a byte stream which could be transformed via transformer into an complex type.
      data underControl:
        implementation-data-type=Dcm_ControlMask_8Type
        variation-point=blueprint-condition=p=l-1=({ecuc(Dcm/DcmConfigSet/DcmDsp/DcmDspDid/DcmDspDidInfoRef-> DcmDspDidInfo/DcmDspDidControl/DcmDspDidControlMaskSize)} == 0x01)
        implementation-data-type=Dcm_ControlMask_16Type
        variation-point=blueprint-condition=p=l-1=({ecuc(Dcm/DcmConfigSet/DcmDsp/DcmDspDid/DcmDspDidInfoRef-> DcmDspDidInfo/DcmDspDidControl/DcmDspDidControlMaskSize)} == 0x02)
        implementation-data-type=Dcm_ControlMask_32Type
        variation-point=blueprint-condition=p=l-1=({ecuc(Dcm/DcmConfigSet/DcmDsp/DcmDspDid/DcmDspDidInfoRef-> DcmDspDidInfo/DcmDspDidControl/DcmDspDidControlMaskSize)} >= 0x03)
      data IOOperationRequest: implementation-data-type=Dcm_IOOperationRequestType
      data controlState: implementation-data-type=Dcm_DID_Struct_DataType, variation-point=blueprint-condition=p=l-1=({ecuc(Dcm/DcmConfigSet/DcmDsp/DcmDspDid/DcmDspDidInfoRef-> DcmDspDidInfo/DcmDspDidControl/DcmDspDidShortTermAdjustment)} == True)
    IOControlResponse: variation-point={short-label=IOControlResponse, blueprint-condition=[l-1=({ecuc(Dcm/DcmConfigSet/DcmDsp/DcmDspDid/DcmDspDidUsePort)} ==(USE_ATOMIC_SENDER_RECEIVER_INTERFACE || USE_ATOMIC_SENDER_RECEIVER_INTERFACE_AS_SERVICE))) &&, l-1=({ecuc(Dcm/DcmConfigSet/DcmDsp/DcmDspDid/DcmDspDidInfoRef-> DcmDspDidInfo/DcmDspDidControl)} != NULL))]}, is-service=true
      data IOOperationResponse: implementation-data-type=Dcm_IOOperationResponseType
package /AUTOSAR/Dcm/ServiceSwComponentTypes_Blueprint
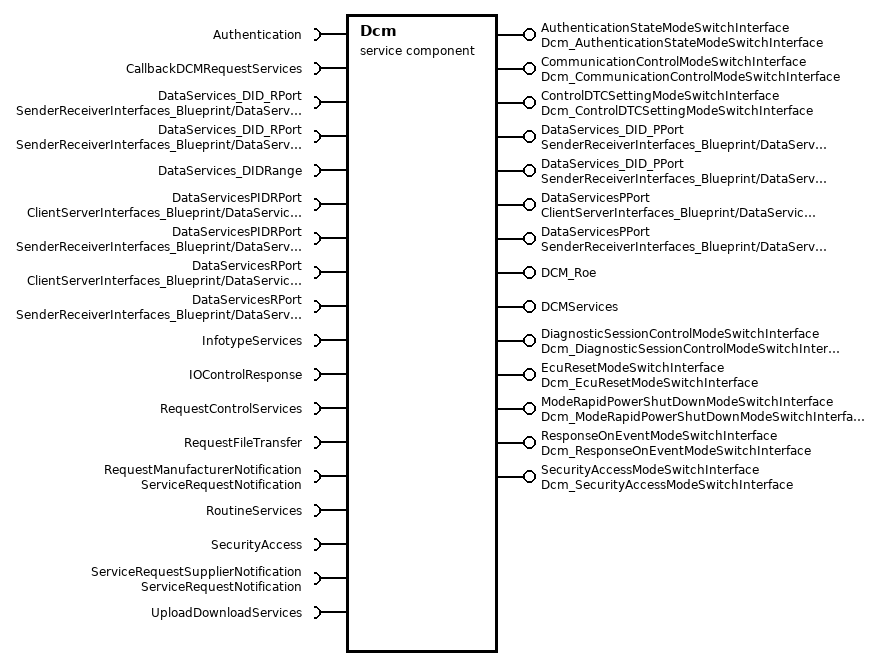
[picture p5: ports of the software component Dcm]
  service sw component type Dcm
    require port Authentication: required-interface=Authentication
    provide port AuthenticationStateModeSwitchInterface: provided-interface=Dcm_AuthenticationStateModeSwitchInterface
    require port CallbackDCMRequestServices: required-interface=CallbackDCMRequestServices
    4 x provide port:
      CommunicationControlModeSwitchInterface: provided-interface=Dcm_CommunicationControlModeSwitchInterface  # A ModeSwitchInterface PPortPrototype used to notify SW-Cs about the communication control of the indicated ComM channel
      ControlDTCSettingModeSwitchInterface: provided-interface=Dcm_ControlDTCSettingModeSwitchInterface  # A ModeSwitchInterface PPortPrototype used to notify SW-Cs about the DTC Setting mode
      DataServices_DID_PPort: variation-point={short-label=DataServices_DID_DataServices_DID_NvD, blueprint-condition=p=l-1=(({ecuc(Dcm/DcmConfigSet/DcmDsp/DcmDspDid/DcmDspDidUsePort)} == (USE_ATOMIC_SENDER_RECEIVER_INTERFACE ) ||({ecuc(Dcm/DcmConfigSet/DcmDsp/DcmDspDid/DcmDspDidUsePort)} == (USE_ATOMIC_SENDER_RECEIVER_INTERFACE_AS_SERVICE ) ||({ecuc(Dcm/DcmConfigSet/DcmDsp/DcmDspDid/DcmDspDidUsePort)} == (USE_ATOMIC_NV_DATA_INTERFACE)) && ({ecuc(Dcm/DcmConfigSet/DcmDsp/DcmDspDid/DcmDspDidInfoRef-> DcmDspDidInfo/DcmDspDidWrite)} == NULL) && (({ecuc(Dcm/DcmConfigSet/DcmDsp/DcmDspDid/DcmDspDidInfoRef-> DcmDspDidInfo/DcmDspDidRead)} != NULL) ||({ecuc(Dcm/DcmConfigSet/DcmDsp/DcmDspDid/DcmDspDidInfoRef-> DcmDspDidInfo/DcmDspDidControl)} !=NULL))}, provided-interface=SenderReceiverInterfaces_Blueprint/DataServices_DID
      DataServices_DID_PPort: variation-point={short-label=DataServices_DID_DataServices_DID_SR, blueprint-condition=p=l-1=(({ecuc(Dcm/DcmConfigSet/DcmDsp/DcmDspDid/DcmDspDidUsePort)} == (USE_ATOMIC_SENDER_RECEIVER_INTERFACE ) ||({ecuc(Dcm/DcmConfigSet/DcmDsp/DcmDspDid/DcmDspDidUsePort)} == (USE_ATOMIC_SENDER_RECEIVER_INTERFACE_AS_SERVICE ) ||({ecuc(Dcm/DcmConfigSet/DcmDsp/DcmDspDid/DcmDspDidUsePort)} == (USE_ATOMIC_NV_DATA_INTERFACE)) && ({ecuc(Dcm/DcmConfigSet/DcmDsp/DcmDspDid/DcmDspDidInfoRef-> DcmDspDidInfo/DcmDspDidWrite)} == NULL) && (({ecuc(Dcm/DcmConfigSet/DcmDsp/DcmDspDid/DcmDspDidInfoRef-> DcmDspDidInfo/DcmDspDidRead)} != NULL) ||({ecuc(Dcm/DcmConfigSet/DcmDsp/DcmDspDid/DcmDspDidInfoRef-> DcmDspDidInfo/DcmDspDidControl)} !=NULL))}, provided-interface=SenderReceiverInterfaces_Blueprint/DataServices_DID
    provide/require port DataServices_DID_PRPort: variation-point={short-label=DataServices_DID_DataServices_DID_NvD, blueprint-condition=p=l-1=(({ecuc(Dcm/DcmConfigSet/DcmDsp/DcmDspDid/DcmDspDidUsePort)} == (USE_ATOMIC_SENDER_RECEIVER_INTERFACE ) ||({ecuc(Dcm/DcmConfigSet/DcmDsp/DcmDspDid/DcmDspDidUsePort)} == (USE_ATOMIC_SENDER_RECEIVER_INTERFACE_AS_SERVICE ) ||({ecuc(Dcm/DcmConfigSet/DcmDsp/DcmDspDid/DcmDspDidUsePort)} == (USE_ATOMIC_NV_DATA_INTERFACE)) && ({ecuc(Dcm/DcmConfigSet/DcmDsp/DcmDspDid/DcmDspDidInfoRef->DcmDspDidInfo/DcmDspDidWrite)} != NULL) && ({ecuc(Dcm/DcmConfigSet/DcmDsp/DcmDspDid/DcmDspDidInfoRef->DcmDspDidInfo/DcmDspDidRead)} != NULL))}, provided-required-interface=SenderReceiverInterfaces_Blueprint/DataServices_DID
    provide/require port DataServices_DID_PRPort: variation-point={short-label=DataServices_DID_DataServices_DID_SR, blueprint-condition=p=l-1=(({ecuc(Dcm/DcmConfigSet/DcmDsp/DcmDspDid/DcmDspDidUsePort)} == (USE_ATOMIC_SENDER_RECEIVER_INTERFACE ) ||({ecuc(Dcm/DcmConfigSet/DcmDsp/DcmDspDid/DcmDspDidUsePort)} == (USE_ATOMIC_SENDER_RECEIVER_INTERFACE_AS_SERVICE ) ||({ecuc(Dcm/DcmConfigSet/DcmDsp/DcmDspDid/DcmDspDidUsePort)} == (USE_ATOMIC_NV_DATA_INTERFACE)) && ({ecuc(Dcm/DcmConfigSet/DcmDsp/DcmDspDid/DcmDspDidInfoRef->DcmDspDidInfo/DcmDspDidWrite)} != NULL) && ({ecuc(Dcm/DcmConfigSet/DcmDsp/DcmDspDid/DcmDspDidInfoRef->DcmDspDidInfo/DcmDspDidRead)} != NULL))}, provided-required-interface=SenderReceiverInterfaces_Blueprint/DataServices_DID
    5 x require port:
      DataServices_DID_RPort: variation-point={short-label=DataServices_DID_DataServices_DID_NvD, blueprint-condition=p=l-1=(({ecuc(Dcm/DcmConfigSet/DcmDsp/DcmDspDid/DcmDspDidUsePort)} == (USE_ATOMIC_SENDER_RECEIVER_INTERFACE ) || ({ecuc(Dcm/DcmConfigSet/DcmDsp/DcmDspDid/DcmDspDidUsePort)} == (USE_ATOMIC_SENDER_RECEIVER_INTERFACE_AS_SERVICE ) ||({ecuc(Dcm/DcmConfigSet/DcmDsp/DcmDspDid/DcmDspDidUsePort)} == (USE_ATOMIC_NV_DATA_INTERFACE)) && ({ecuc(Dcm/DcmConfigSet/DcmDsp/DcmDspDid/DcmDspDidInfoRef->DcmDspDidInfo/DcmDspDidWrite)} == NULL) && (({ecuc(Dcm/DcmConfigSet/DcmDsp/DcmDspDid/DcmDspDidInfoRef->DcmDspDidInfo/DcmDspDidRead)} != NULL) ||({ecuc(Dcm/DcmConfigSet/DcmDsp/DcmDspDid/DcmDspDidInfoRef->DcmDspDidInfo/DcmDspDidControl)} !=NULL))}, required-interface=SenderReceiverInterfaces_Blueprint/DataServices_DID
      DataServices_DID_RPort: variation-point={short-label=DataServices_DID_DataServices_DID_SR, blueprint-condition=p=l-1=(({ecuc(Dcm/DcmConfigSet/DcmDsp/DcmDspDid/DcmDspDidUsePort)} == (USE_ATOMIC_SENDER_RECEIVER_INTERFACE ) || ({ecuc(Dcm/DcmConfigSet/DcmDsp/DcmDspDid/DcmDspDidUsePort)} == (USE_ATOMIC_SENDER_RECEIVER_INTERFACE_AS_SERVICE ) ||({ecuc(Dcm/DcmConfigSet/DcmDsp/DcmDspDid/DcmDspDidUsePort)} == (USE_ATOMIC_NV_DATA_INTERFACE)) && ({ecuc(Dcm/DcmConfigSet/DcmDsp/DcmDspDid/DcmDspDidInfoRef->DcmDspDidInfo/DcmDspDidWrite)} == NULL) && (({ecuc(Dcm/DcmConfigSet/DcmDsp/DcmDspDid/DcmDspDidInfoRef->DcmDspDidInfo/DcmDspDidRead)} != NULL) ||({ecuc(Dcm/DcmConfigSet/DcmDsp/DcmDspDid/DcmDspDidInfoRef->DcmDspDidInfo/DcmDspDidControl)} !=NULL))}, required-interface=SenderReceiverInterfaces_Blueprint/DataServices_DID
      DataServices_DIDRange: variation-point=blueprint-condition=p=l-1={ecuc(Dcm/DcmConfigSet/DcmDsp/DcmDspDidRange.DcmDspDidRangeUsePort)} == TRUE, required-interface=DataServices_DIDRange
      DataServicesPIDRPort: variation-point={short-label=DataServices_DataServicesCS, blueprint-condition=[l-1=( {ecuc(Dcm/DcmConfigSet/DcmDsp/DcmDspPid/DcmDspPidData/DcmDspPidService01/DcmDspPidDataUsePort)} ==(USE_DATA_SYNCH_CLIENT_SERVER ||USE_DATA_SENDER_RECEIVER ||USE_DATA_SENDER_RECEIVER_AS_SERVICE)), l-1=((( {ecuc(Dcm/DcmConfigSet/DcmDsp/DcmDspDid/DcmDspDidUsePort)} == USE_DATA_ELEMENT_SPECIFIC_INTERFACES)) || ({ecuc(Dcm/DcmConfigSet/DcmDsp/DcmDspData.DcmDspDataUsePort)} == USE_DATA_SYNCH_CLIENT_SERVER) || ({ecuc(Dcm/DcmConfigSet/DcmDsp/DcmDspData.DcmDspDataUsePort)} ==USE_DATA_ASYNCH_CLIENT_SERVER) || ({ecuc(Dcm/cmConfigSet/DcmDsp/DcmDspData.DcmDspDataUsePort)} ==USE_DATA_ASYNCH_CLIENT_SERVER_ERROR) || ({ecuc(Dcm/DcmConfigSet/DcmDsp/DcmDspPid/DcmDspPidData/DcmDspPidService01.DcmDspPidDataUsePort)} ==USE_DATA_SYNCH_CLIENT_SERVER) )]}, required-interface=ClientServerInterfaces_Blueprint/DataServices
      DataServicesPIDRPort: variation-point={short-label=DataServices_DataServicesSR, blueprint-condition=p=l-1=( {ecuc(Dcm/DcmConfigSet/DcmDsp/DcmDspPid/DcmDspPidData/DcmDspPidService01/DcmDspPidDataUsePort)} ==(USE_DATA_SYNCH_CLIENT_SERVER ||USE_DATA_SENDER_RECEIVER ||USE_DATA_SENDER_RECEIVER_AS_SERVICE))}, required-interface=SenderReceiverInterfaces_Blueprint/DataServices
    provide port DataServicesPPort: variation-point={short-label=DataServices_DataServicesCS, blueprint-condition=[l-1=((( {ecuc(Dcm/DcmConfigSet/DcmDsp/DcmDspDid/DcmDspDidUsePort)} == USE_DATA_ELEMENT_SPECIFIC_INTERFACES)) && ({ecuc(Dcm/DcmConfigSet/DcmDsp/DcmDspData/DcmDspDataUsePort)} == (USE_DATA_SENDER_RECEIVER ||USE_DATA_SENDER_RECEIVER_AS_SERVICE))) &&({ecuc(Dcm/DcmConfigSet/DcmDsp/DcmDspDid/DcmDspDidInfoRef-> DcmDspDidInfo/DcmDspDidWrite)} != NULL) && ({ecuc(Dcm/DcmConfigSet/DcmDsp/DcmDspDid/DcmDspDidInfoRef-> DcmDspDidInfo/DcmDspDidRead)} == NULL), l-1=((( {ecuc(Dcm/DcmConfigSet/DcmDsp/DcmDspDid/DcmDspDidUsePort)} == USE_DATA_ELEMENT_SPECIFIC_INTERFACES)) || ({ecuc(Dcm/DcmConfigSet/DcmDsp/DcmDspData.DcmDspDataUsePort)} == USE_DATA_SYNCH_CLIENT_SERVER) || ({ecuc(Dcm/DcmConfigSet/DcmDsp/DcmDspData.DcmDspDataUsePort)} ==USE_DATA_ASYNCH_CLIENT_SERVER) || ({ecuc(Dcm/cmConfigSet/DcmDsp/DcmDspData.DcmDspDataUsePort)} ==USE_DATA_ASYNCH_CLIENT_SERVER_ERROR) || ({ecuc(Dcm/DcmConfigSet/DcmDsp/DcmDspPid/DcmDspPidData/DcmDspPidService01.DcmDspPidDataUsePort)} ==USE_DATA_SYNCH_CLIENT_SERVER) )]}, provided-interface=ClientServerInterfaces_Blueprint/DataServices
    provide port DataServicesPPort: variation-point={short-label=DataServices_DataServicesSR, blueprint-condition=p=l-1=((( {ecuc(Dcm/DcmConfigSet/DcmDsp/DcmDspDid/DcmDspDidUsePort)} == USE_DATA_ELEMENT_SPECIFIC_INTERFACES)) && ({ecuc(Dcm/DcmConfigSet/DcmDsp/DcmDspData/DcmDspDataUsePort)} == (USE_DATA_SENDER_RECEIVER ||USE_DATA_SENDER_RECEIVER_AS_SERVICE))) &&({ecuc(Dcm/DcmConfigSet/DcmDsp/DcmDspDid/DcmDspDidInfoRef-> DcmDspDidInfo/DcmDspDidWrite)} != NULL) && ({ecuc(Dcm/DcmConfigSet/DcmDsp/DcmDspDid/DcmDspDidInfoRef-> DcmDspDidInfo/DcmDspDidRead)} == NULL)}, provided-interface=SenderReceiverInterfaces_Blueprint/DataServices
    provide/require port DataServicesPRPort: variation-point=blueprint-condition=p=l-1=((( {ecuc(Dcm/DcmConfigSet/DcmDsp/DcmDspDid/DcmDspDidUsePort)} == USE_DATA_ELEMENT_SPECIFIC_INTERFACES)) &&({ecuc(Dcm/DcmConfigSet/DcmDsp/DcmDspData/DcmDspDataUsePort)} == (USE_DATA_SENDER_RECEIVER ||USE_DATA_SENDER_RECEIVER_AS_SERVICE))) &&({ecuc(Dcm/DcmConfigSet/DcmDsp/DcmDspDid/DcmDspDidInfoRef-> DcmDspDidInfo/DcmDspDidWrite)} != NULL) && ({ecuc(Dcm/DcmConfigSet/DcmDsp/DcmDspDid/DcmDspDidInfoRef-> DcmDspDidInfo/DcmDspDidRead)} != NULL), provided-required-interface=SenderReceiverInterfaces_Blueprint/DataServices
    require port DataServicesRPort: variation-point={short-label=DataServices_DataServicesCS, blueprint-condition=[l-1=((( {ecuc(Dcm/DcmConfigSet/DcmDsp/DcmDspDid/DcmDspDidUsePort)} == USE_DATA_ELEMENT_SPECIFIC_INTERFACES)) && ({ecuc(Dcm/DcmConfigSet/DcmDsp/DcmDspData/DcmDspDataUsePort)} == (USE_DATA_SENDER_RECEIVER ||USE_DATA_SENDER_RECEIVER_AS_SERVICE))) && ({ecuc(Dcm/DcmConfigSet/DcmDsp/DcmDspDid/DcmDspDidInfoRef-> DcmDspDidInfo/DcmDspDidWrite)} == NULL) && (({ecuc(Dcm/DcmConfigSet/DcmDsp/DcmDspDid/DcmDspDidInfoRef-> DcmDspDidInfo/DcmDspDidRead)} != NULL))), l-1=((( {ecuc(Dcm/DcmConfigSet/DcmDsp/DcmDspDid/DcmDspDidUsePort)} == USE_DATA_ELEMENT_SPECIFIC_INTERFACES)) || ({ecuc(Dcm/DcmConfigSet/DcmDsp/DcmDspData.DcmDspDataUsePort)} == USE_DATA_SYNCH_CLIENT_SERVER) || ({ecuc(Dcm/DcmConfigSet/DcmDsp/DcmDspData.DcmDspDataUsePort)} ==USE_DATA_ASYNCH_CLIENT_SERVER) || ({ecuc(Dcm/cmConfigSet/DcmDsp/DcmDspData.DcmDspDataUsePort)} ==USE_DATA_ASYNCH_CLIENT_SERVER_ERROR) || ({ecuc(Dcm/DcmConfigSet/DcmDsp/DcmDspPid/DcmDspPidData/DcmDspPidService01.DcmDspPidDataUsePort)} ==USE_DATA_SYNCH_CLIENT_SERVER) )]}, required-interface=ClientServerInterfaces_Blueprint/DataServices
    require port DataServicesRPort: variation-point={short-label=DataServices_DataServicesSR, blueprint-condition=p=l-1=((( {ecuc(Dcm/DcmConfigSet/DcmDsp/DcmDspDid/DcmDspDidUsePort)} == USE_DATA_ELEMENT_SPECIFIC_INTERFACES)) && ({ecuc(Dcm/DcmConfigSet/DcmDsp/DcmDspData/DcmDspDataUsePort)} == (USE_DATA_SENDER_RECEIVER ||USE_DATA_SENDER_RECEIVER_AS_SERVICE))) && ({ecuc(Dcm/DcmConfigSet/DcmDsp/DcmDspDid/DcmDspDidInfoRef-> DcmDspDidInfo/DcmDspDidWrite)} == NULL) && (({ecuc(Dcm/DcmConfigSet/DcmDsp/DcmDspDid/DcmDspDidInfoRef-> DcmDspDidInfo/DcmDspDidRead)} != NULL)))}, required-interface=SenderReceiverInterfaces_Blueprint/DataServices
    4 x provide port:
      DCM_Roe: variation-point=blueprint-condition=p=l-1={ecuc(Dcm/DcmConfigSet/DcmDsp/DcmDspRoe/DcmDspRoeEvent)}, provided-interface=DCM_Roe
      DCMServices: provided-interface=DCMServices
      DiagnosticSessionControlModeSwitchInterface: provided-interface=Dcm_DiagnosticSessionControlModeSwitchInterface  # A ModeSwitchInterface PPortPrototype used to notify SW-Cs about the current Diagnostic Session
      EcuResetModeSwitchInterface: provided-interface=Dcm_EcuResetModeSwitchInterface  # A ModeSwitchInterface PPortPrototype used to notify SW-Cs about an upcoming ECU Reset and its type
    require port InfotypeServices: variation-point=blueprint-condition=p=l-1={ecuc(Dcm/DcmConfigSet/DcmDsp/DcmDspVehInfo/DcmDspVehInfoData/DcmDspVehInfoDataUsePort)}==TRUE, required-interface=InfotypeServices
    provide/require port IOControlRequest: variation-point=blueprint-condition=p=l-1=(({ecuc(Dcm/DcmConfigSet/DcmDsp/DcmDspDid/DcmDspDidUsePort)} == (USE_ATOMIC_SENDER_RECEIVER_INTERFACE || USE_DATA_SENDER_RECEIVER_AS_SERVICE))) && ({ecuc(Dcm/DcmConfigSet/DcmDsp/DcmDspDid/DcmDspDidInfoRef-> DcmDspDidInfo/DcmDspDidControl)} != NULL), provided-required-interface=IOControlRequest
    require port IOControlResponse: variation-point=blueprint-condition=p=l-1=(({ecuc(Dcm/DcmConfigSet/DcmDsp/DcmDspDid/DcmDspDidUsePort)} == (USE_ATOMIC_SENDER_RECEIVER_INTERFACE || USE_DATA_SENDER_RECEIVER_AS_SERVICE))) &&({ecuc(Dcm/DcmConfigSet/DcmDsp/DcmDspDid/DcmDspDidInfoRef-> DcmDspDidInfo/DcmDspDidControl)} != NULL), required-interface=IOControlResponse
    provide port ModeRapidPowerShutDownModeSwitchInterface: provided-interface=Dcm_ModeRapidPowerShutDownModeSwitchInterface  # A ModeSwitchInterface PPortPrototype used to notify SW-Cs about the rapid power shut down mode
    require port RequestControlServices: required-interface=RequestControlServices
    require port RequestFileTransfer: variation-point=blueprint-condition=p=l-1=({ecuc(Dcm/DcmConfigSet/DcmDsp/DcmDspRequestFileTransfer/DcmRequestFileTransferUsePort)} == TRUE), required-interface=RequestFileTransfer
    require port RequestManufacturerNotification: variation-point=blueprint-condition=p=l-1=({ecuc(Dcm/DcmConfigSet/DcmDsd/DcmDsdServiceRequestManufacturerNotification)} != NULL), required-interface=ServiceRequestNotification
    provide port ResponseOnEventModeSwitchInterface: provided-interface=Dcm_ResponseOnEventModeSwitchInterface  # A ModeSwitchInterface PPortPrototype used to notify SW-Cs about the mode of the indicated Response On Event
    require port RoutineServices: variation-point=blueprint-condition=p=l-1={ecuc(Dcm/DcmConfigSet/DcmDsp/DcmDspRoutine.DcmDspRoutineUsePort)} == TRUE, required-interface=RoutineServices
    require port SecurityAccess: variation-point=blueprint-condition=p=l-1={ecuc(Dcm/DcmConfigSet/DcmDsp/DcmDspSecurity/DcmDspSecurityRow.DcmDspSecurityUsePort)} == USE_ASYNCH_CLIENT_SERVER, required-interface=SecurityAccess
    provide port SecurityAccessModeSwitchInterface: provided-interface=Dcm_SecurityAccessModeSwitchInterface  # A ModeSwitchInterface PPortPrototype used to notify SW-Cs about the current Security Level
    require port ServiceRequestSupplierNotification: variation-point=blueprint-condition=p=l-1=({ecuc(Dcm/DcmConfigSet/DcmDsd/DcmDsdServiceRequestSupplierNotification)} != NULL), required-interface=ServiceRequestNotification
    require port UploadDownloadServices: variation-point=blueprint-condition=p=l-1={ecuc(Dcm/DcmConfigSet/DcmDsp/DcmDspMemoryTransfer.DcmDspMemoryTransferUsePort)} == TRUE), required-interface=UploadDownloadServices
    behavior DcmInternalBehavior
      port-api-options:
        {port-defined-argument-value{value=undefined, value-type=uint16}, port=Authentication}
        {port-defined-argument-value{value=undefined, value-type=uint8}, port=DCM_Roe}
package /AUTOSAR/Dcm/ModeDeclarationGroups_Blueprint
  8 x mode declaration group, all with category=EXPLICIT_ORDER, on-transition-value=255:
    DcmAuthenticationState: initial-mode=DCM_DEAUTHENTICATED
      mode DCM_DEAUTHENTICATED: value=0
      mode DCM_AUTHENTICATED: value=1
    DcmCommunicationControl: initial-mode=DCM_ENABLE_RX_TX_NORM_NM
      12 x mode:
        DCM_ENABLE_RX_TX_NORM: value=0
        DCM_ENABLE_RX_DISABLE_TX_NORM: value=1
        DCM_DISABLE_RX_ENABLE_TX_NORM: value=2
        DCM_DISABLE_RX_TX_NORMAL: value=3
        DCM_ENABLE_RX_TX_NM: value=4
        DCM_ENABLE_RX_DISABLE_TX_NM: value=5
        DCM_DISABLE_RX_ENABLE_TX_NM: value=6
        DCM_DISABLE_RX_TX_NM: value=7
        DCM_ENABLE_RX_TX_NORM_NM: value=8
        DCM_ENABLE_RX_DISABLE_TX_NORM_NM: value=9
        DCM_DISABLE_RX_ENABLE_TX_NORM_NM: value=10
        DCM_DISABLE_RX_TX_NORM_NM: value=11
    DcmControlDTCSetting: initial-mode=DCM_ENABLEDTCSETTING
      mode DCM_ENABLEDTCSETTING: value=0
      mode DCM_DISABLEDTCSETTING: value=1
    DcmDiagnosticSessionControl: initial-mode=DCM_DEFAULT_SESSION
      4 x mode:
        DCM_DEFAULT_SESSION: value=0
        DCM_PROGRAMMING_SESSION: value=1
        DCM_EXTENDED_DIAGNOSTIC_SESSION: value=2
        DCM_SAFETY_SYSTEM_DIAGNOSTIC_SESSION: value=3
    DcmEcuReset: initial-mode=DCM_NONE
      7 x mode:
        DCM_NONE: value=0
        DCM_HARD: value=1
        DCM_KEYONOFF: value=2
        DCM_SOFT: value=3
        DCM_JUMPTOBOOTLOADER: value=4
        DCM_JUMPTOSYSSUPPLIERBOOTLOADER: value=5
        DCM_EXECUTE: value=6
    DcmModeRapidPowerShutDown: initial-mode=DCM_ENABLE_RAPIDPOWERSHUTDOWN
      mode DCM_ENABLE_RAPIDPOWERSHUTDOWN: value=0
      mode DCM_DISABLE_RAPIDPOWERSHUTDOWN: value=1
    DcmResponseOnEvent: initial-mode=DCM_EVENT_CLEARED
      mode DCM_EVENT_STARTED: value=0
      mode DCM_EVENT_STOPPED: value=1
      mode DCM_EVENT_CLEARED: value=2
    DcmSecurityAccess: initial-mode=DCM_SEC_LEV_LOCKED
      mode DCM_SEC_LEV_LOCKED: value=0
package /AUTOSAR/Dcm/ModeSwitchInterfaces_Blueprint
  8 x mode switch interface, all with is-service=true:
    Dcm_AuthenticationStateModeSwitchInterface
      mode group authenticationState: type=DcmAuthenticationState
    Dcm_CommunicationControlModeSwitchInterface  # A SW-C that wants to get informed about the communication control of a ComM channel requires the ModeSwitchInterface Dcm_CommunicationControlModeSwitchInterface
      mode group communicationControl: type=DcmCommunicationControl
    Dcm_ControlDTCSettingModeSwitchInterface  # A SW-C that wants to get informed about the DTC Setting mode requires the ModeSwitchInterface Dcm_ControlDTCSettingModeSwitchInterface
      mode group controlDTCSetting: type=DcmControlDTCSetting
    Dcm_DiagnosticSessionControlModeSwitchInterface  # A SW-C that wants to get informed about the current Diagnostic Session requires the ModeSwitchInterface Dcm_DiagnosticSessionControlModeSwitchInterface
      mode group diagnosticSession: type=DcmDiagnosticSessionControl
    Dcm_EcuResetModeSwitchInterface  # A SW-C that wants to get informed about an upcoming ECU Reset requires the ModeSwitchInterface Dcm_EcuResetModeSwitchInterface
      mode group ecuReset: type=DcmEcuReset
    Dcm_ModeRapidPowerShutDownModeSwitchInterface  # A SW-C that wants to get informed about the rapid power shut down mode requires the ModeSwitchInterface Dcm_ModeRapidPowerShutDownModeSwitchInterface
      mode group modeRapidPowerShutDown: type=DcmModeRapidPowerShutDown
    Dcm_ResponseOnEventModeSwitchInterface  # A SW-C that wants to get informed about a Response On Event mode requires the ModeSwitchInterface Dcm_ResponseOnEventModeSwitchInterface
      mode group responseOnEvent: type=DcmResponseOnEvent
    Dcm_SecurityAccessModeSwitchInterface  # A SW-C that wants to get informed about the current Security Level requires the ModeSwitchInterface Dcm_SecurityAccessModeSwitchInterface
      mode group securityAccess: type=DcmSecurityAccess
package /AUTOSAR/NvM/ClientServerInterfaces_Blueprint
  5 x client server interface, all with is-service=true:
    NvMAdmin
      operation SetBlockProtection: possible-error=[NvMAdmin/E_OK, NvMAdmin/E_NOT_OK], variation-point=blueprint-condition=p=l-1={ecuc(NvM/NvMCommon/NvMApiConfigClass)} == NVM_API_CONFIG_CLASS_3  # Service for setting/resetting the write protection for a NV block.
        arg ProtectionEnabled: type=boolean, direction=IN
      error E_OK: error-code=0  # Operation successful
      error E_NOT_OK: error-code=1  # Operation failed
    NvMMirror
      operation ReadRamBlockFromNvM: possible-error=[NvMMirror/E_OK, NvMMirror/E_NOT_OK]  # Block specific callback routine which shall be called in order to let the application copy data from NvM module's mirror to RAM block.
        arg SrcPtr: type=ConstVoidPtr, direction=IN  # The parameter "SrcPtr" shall be typed by an ImplementationDataType of category DATA_REFERENCE with the pointer target void to pass an address (pointer) to the RAM Block.
      operation WriteRamBlockToNvM: possible-error=[NvMMirror/E_OK, NvMMirror/E_NOT_OK]  # Block specific callback routine which shall be called in order to let the application copy data from RAM block to NvM module's mirror.
        arg DstPtr: type=VoidPtr, direction=IN  # The parameter "DstPtr" shall be typed by an ImplementationDataType of category DATA_REFERENCE with the pointer target void to pass an address (pointer) to the RAM Block.
      error E_OK: error-code=0  # Operation successful
      error E_NOT_OK: error-code=1  # Operation failed
    NvMNotifyInitBlock  # Callback that is called by the NvM module when default data needs to be restored to the RAM image
      operation InitBlock: possible-error=NvMNotifyInitBlock/E_OK  # This callback is called if the initialization of a block has completed.
        arg InitBlockRequest: type=NvM_InitBlockRequestType, direction=IN  # --
      error E_OK: error-code=0  # Operation successful
    NvMNotifyJobFinished  # Callback that is called when a job has finished
      operation JobFinished: possible-error=NvMNotifyJobFinished/E_OK  # Callback that gets called if a job has finished
        arg BlockRequest: type=NvM_BlockRequestType, direction=IN
        arg JobResult: type=NvM_RequestResultType, direction=IN
      error E_OK: error-code=0  # Operation successful
    NvMService
      12 x operation, all with possible-error=[NvMService/E_OK, NvMService/E_NOT_OK]:
        EraseBlock: variation-point=blueprint-condition=p=l-1={ecuc(NvM/NvMCommon/NvMApiConfigClass)} == NVM_API_CONFIG_CLASS_3  # Service to erase a NV block.
        GetDataIndex: variation-point=blueprint-condition=p=l-1=(({ecuc(NvM/NvMCommon/NvMApiConfigClass)} == NVM_API_CONFIG_CLASS_2) || ({ecuc(NvM/NvMCommon/NvMApiConfigClass)} == NVM_API_CONFIG_CLASS_3)) && (count({ecuc(NvM/NvMBlockDescriptor/NvMBlockManagementType)} == NVM_BLOCK_DATASET) > 0)  # Service for getting the currently set DataIndex of a dataset NVRAM block
          arg DataIndexPtr: type=uint8, direction=OUT
        GetErrorStatus  # Service to read the block dependent error/status information.
          arg RequestResultPtr: type=NvM_RequestResultType, direction=OUT
        InvalidateNvBlock: variation-point=blueprint-condition=p=l-1={ecuc(NvM/NvMCommon/NvMApiConfigClass)} == NVM_API_CONFIG_CLASS_3  # Service to invalidate a NV block.
        ReadBlock: variation-point=blueprint-condition=p=l-1=({ecuc(NvM/NvMCommon/NvMApiConfigClass)} == NVM_API_CONFIG_CLASS_2 || {ecuc(NvM/NvMCommon/NvMApiConfigClass)} == NVM_API_CONFIG_CLASS_3)  # Service to copy the data of the NV block to its corresponding RAM block.
          arg DstPtr: type=VoidPtr, direction=IN  # The parameter "DstPtr" shall be typed by an ImplementationDataType of category DATA_REFERENCE with the pointer target void to pass an address (pointer) to the RAM Block.
        ReadPRAMBlock: variation-point=blueprint-condition=p=l-1=({ecuc(NvM/NvMCommon/NvMApiConfigClass)} == NVM_API_CONFIG_CLASS_2 || {ecuc(NvM/NvMCommon/NvMApiConfigClass)} == NVM_API_CONFIG_CLASS_3)
        RestoreBlockDefaults: variation-point=blueprint-condition=p=l-1=({ecuc(NvM/NvMCommon/NvMApiConfigClass)} == NVM_API_CONFIG_CLASS_2 || {ecuc(NvM/NvMCommon/NvMApiConfigClass)} == NVM_API_CONFIG_CLASS_3)  # Service to restore the default data to its corresponding RAM block.
          arg DstPtr: type=VoidPtr, direction=IN  # The parameter "DstPtr" shall be typed by an ImplementationDataType of category DATA_REFERENCE with the pointer target void to pass an address (pointer) to the RAM Block.
        RestorePRAMBlockDefaults: variation-point=blueprint-condition=p=l-1=({ecuc(NvM/NvMCommon/NvMApiConfigClass)} == NVM_API_CONFIG_CLASS_2 || {ecuc(NvM/NvMCommon/NvMApiConfigClass)} == NVM_API_CONFIG_CLASS_3)
        SetDataIndex: variation-point=blueprint-condition=p=l-1=(({ecuc(NvM/NvMCommon/NvMApiConfigClass)} == NVM_API_CONFIG_CLASS_2) || ({ecuc(NvM/NvMCommon/NvMApiConfigClass)} == NVM_API_CONFIG_CLASS_3)) && (count({ecuc(NvM/NvMBlockDescriptor/NvMBlockManagementType)} == NVM_BLOCK_DATASET) > 0)  # Service for setting the DataIndex of a dataset NVRAM block.
          arg DataIndex: type=uint8, direction=IN
        SetRamBlockStatus: variation-point=blueprint-condition=p=l-1={ecuc(NvM/NvMBlockDescriptor/NvMBlockUseSetRamBlockStatus)} == true  # Service for setting the RAM block status of an NVRAM block.
          arg BlockChanged: type=boolean, direction=IN
        WriteBlock: variation-point=blueprint-condition=p=l-1=({ecuc(NvM/NvMCommon/NvMApiConfigClass)} == NVM_API_CONFIG_CLASS_2 || {ecuc(NvM/NvMCommon/NvMApiConfigClass)} == NVM_API_CONFIG_CLASS_3)  # Service to copy the data of the RAM block to its corresponding NV block.
          arg SrcPtr: type=ConstVoidPtr, direction=IN  # The parameter "SrcPtr" shall be typed by an ImplementationDataType of category DATA_REFERENCE with the pointer target void to pass an address (pointer) to the RAM Block.
        WritePRAMBlock: variation-point=blueprint-condition=p=l-1=({ecuc(NvM/NvMCommon/NvMApiConfigClass)} == NVM_API_CONFIG_CLASS_2 || {ecuc(NvM/NvMCommon/NvMApiConfigClass)} == NVM_API_CONFIG_CLASS_3)
      error E_OK: error-code=0  # Operation successful
      error E_NOT_OK: error-code=1  # Operation failed
package /AUTOSAR/NvM/ServiceSwComponentTypes_Blueprint
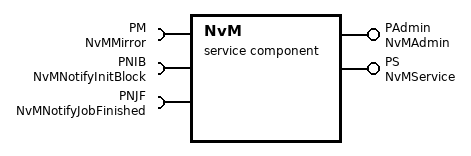
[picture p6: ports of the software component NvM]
  service sw component type NvM
    provide port PAdmin: provided-interface=NvMAdmin
    require port PM: required-interface=NvMMirror
    require port PNIB: required-interface=NvMNotifyInitBlock
    require port PNJF: required-interface=NvMNotifyJobFinished
    provide port PS: provided-interface=NvMService
    behavior NvMInternalBehavior
      port-api-options:
        {port-defined-argument-value{value=undefined, value-type=NvM_BlockIdType}, port=PAdmin}
        {port-defined-argument-value{value=undefined, value-type=NvM_BlockIdType}, port=PS}
